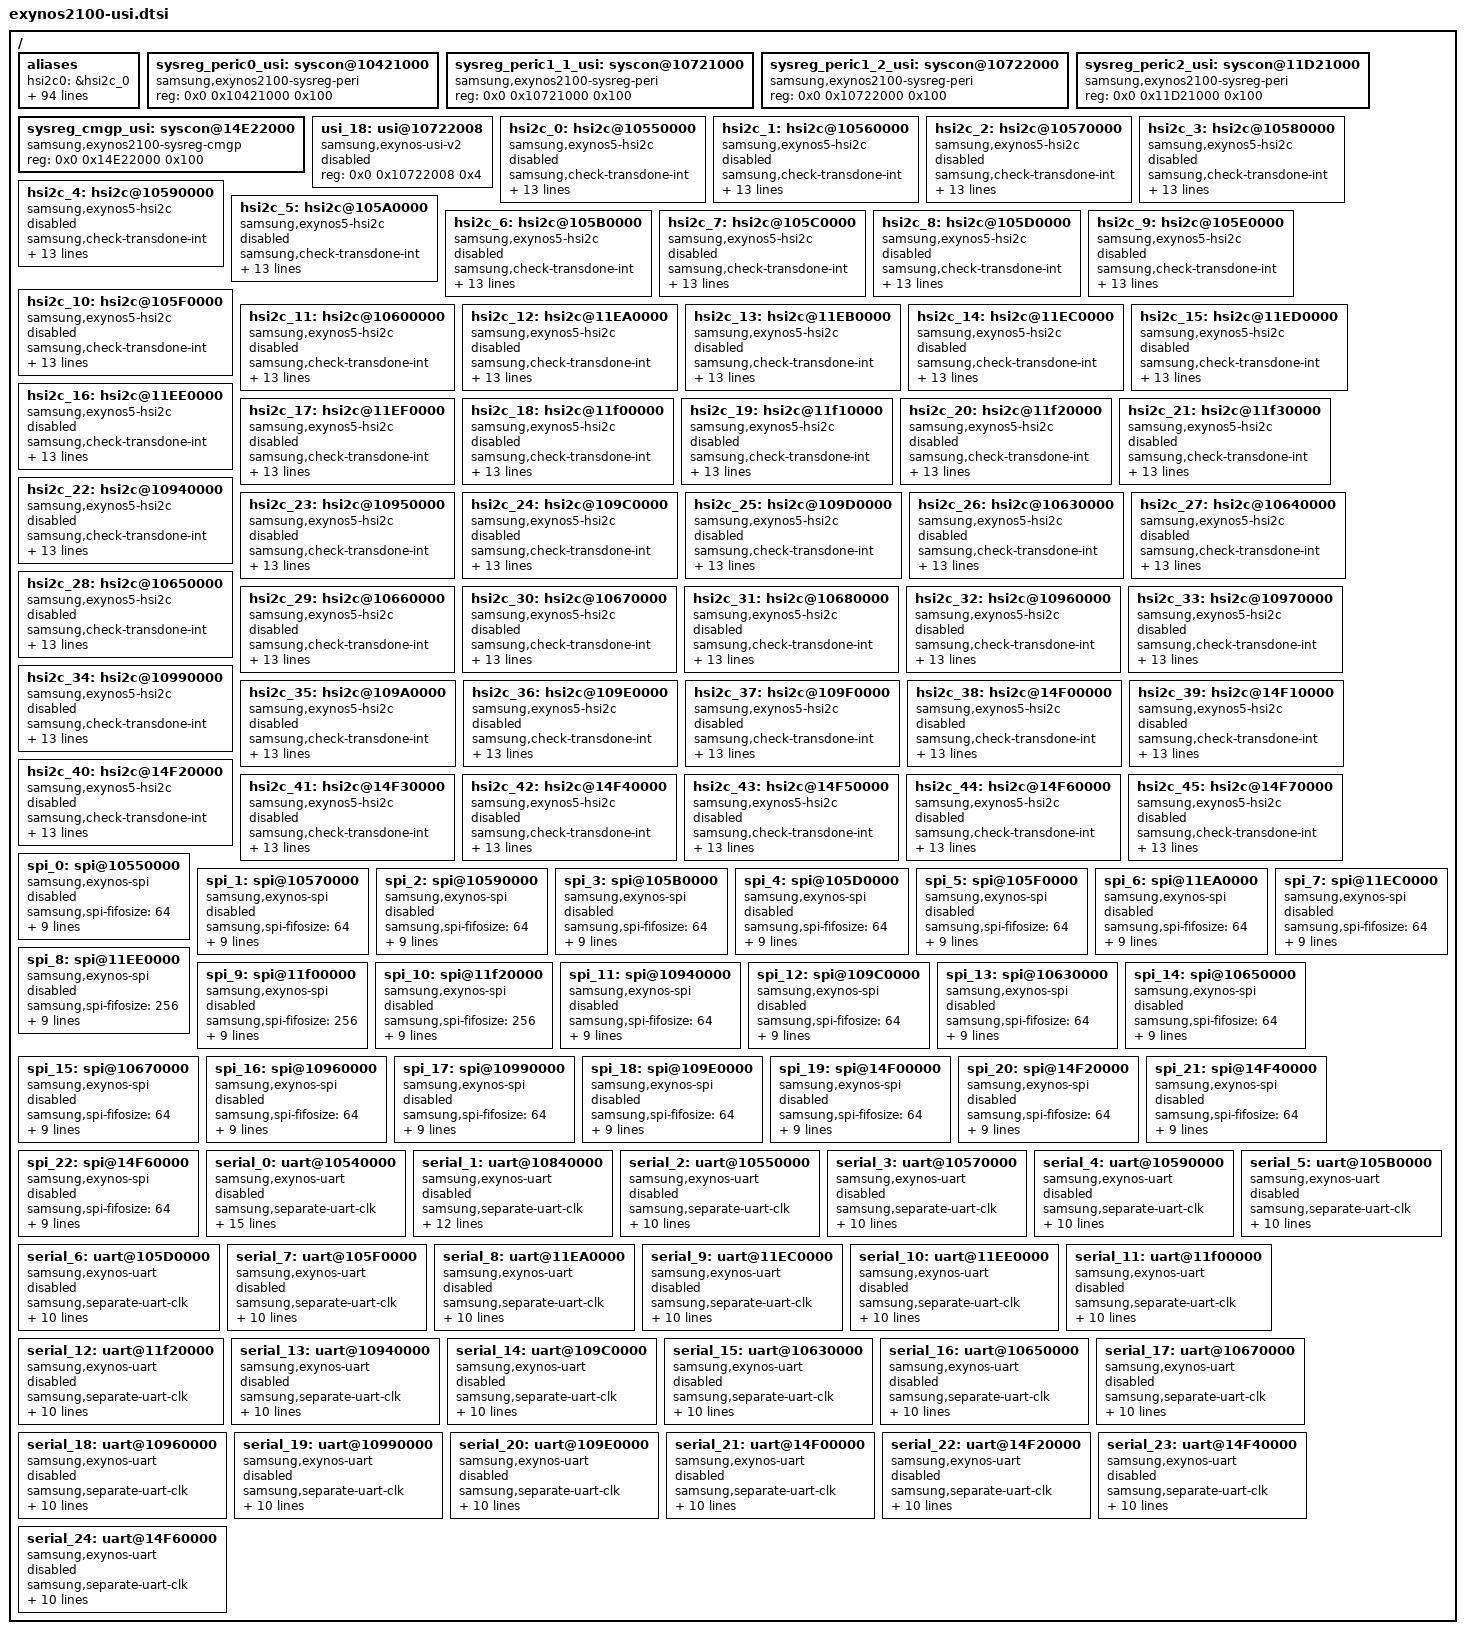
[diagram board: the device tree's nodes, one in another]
/*
 * Samsung's Exynos9830 SoC USI device tree source
 *
 * Copyright (c) 2019 Samsung Electronics Co., Ltd.
 *		http://www.samsung.com
 *
 * Samsung's Exynos9830 SoC USI channels are listed as device
 * tree nodes are listed in this file.
 *
 * This program is free software; you can redistribute it and/or modify
 * it under the terms of the GNU General Public License version 2 as
 * published by the Free Software Foundation.
*/

/ {
	aliases {
		hsi2c0 = &hsi2c_0;
		hsi2c1 = &hsi2c_1;
		hsi2c2 = &hsi2c_2;
		hsi2c3 = &hsi2c_3;
		hsi2c4 = &hsi2c_4;
		hsi2c5 = &hsi2c_5;
		hsi2c6 = &hsi2c_6;
		hsi2c7 = &hsi2c_7;
		hsi2c8 = &hsi2c_8;
		hsi2c9 = &hsi2c_9;
		hsi2c10 = &hsi2c_10;
		hsi2c11 = &hsi2c_11;
		hsi2c12 = &hsi2c_12;
		hsi2c13 = &hsi2c_13;
		hsi2c14 = &hsi2c_14;
		hsi2c15 = &hsi2c_15;
		hsi2c16 = &hsi2c_16;
		hsi2c17 = &hsi2c_17;
		hsi2c18 = &hsi2c_18;
		hsi2c19 = &hsi2c_19;
		hsi2c20 = &hsi2c_20;
		hsi2c21 = &hsi2c_21;
		hsi2c22 = &hsi2c_22;
		hsi2c23 = &hsi2c_23;
		hsi2c24 = &hsi2c_24;
		hsi2c25 = &hsi2c_25;
		hsi2c26 = &hsi2c_26;
		hsi2c27 = &hsi2c_27;
		hsi2c28 = &hsi2c_28;
		hsi2c29 = &hsi2c_29;
		hsi2c30 = &hsi2c_30;
		hsi2c31 = &hsi2c_31;
		hsi2c32 = &hsi2c_32;
		hsi2c33 = &hsi2c_33;
		hsi2c34 = &hsi2c_34;
		hsi2c35 = &hsi2c_35;
		hsi2c36 = &hsi2c_36;
		hsi2c37 = &hsi2c_37;
		hsi2c38 = &hsi2c_38;
		hsi2c39 = &hsi2c_39;
		hsi2c40 = &hsi2c_40;
		hsi2c41 = &hsi2c_41;
		hsi2c42 = &hsi2c_42;
		hsi2c43 = &hsi2c_43;
		hsi2c44 = &hsi2c_44;
		hsi2c45 = &hsi2c_45;
		spi0 = &spi_0;
		spi1 = &spi_1;
		spi2 = &spi_2;
		spi3 = &spi_3;
		spi4 = &spi_4;
		spi5 = &spi_5;
		spi6 = &spi_6;
		spi7 = &spi_7;
		spi8 = &spi_8;
		spi9 = &spi_9;
		spi10 = &spi_10;
		spi11 = &spi_11;
		spi12 = &spi_12;
		spi13 = &spi_13;
		spi14 = &spi_14;
		spi15 = &spi_15;
		spi16 = &spi_16;
		spi17 = &spi_17;
		spi18 = &spi_18;
		spi19 = &spi_19;
		spi20 = &spi_20;
		spi21 = &spi_21;
		spi22 = &spi_22;
		uart0 = &serial_0;
		uart1 = &serial_1;
		uart2 = &serial_2;
		uart3 = &serial_3;
		uart4 = &serial_4;
		uart5 = &serial_5;
		uart6 = &serial_6;
		uart7 = &serial_7;
		uart8 = &serial_8;
		uart9 = &serial_9;
		uart10 = &serial_10;
		uart11 = &serial_11;
		uart12 = &serial_12;
		uart13 = &serial_13;
		uart14 = &serial_14;
		uart15 = &serial_15;
		uart16 = &serial_16;
		uart17 = &serial_17;
		uart18 = &serial_18;
		uart19 = &serial_19;
		uart20 = &serial_20;
		uart21 = &serial_21;
		uart22 = &serial_22;
		uart23 = &serial_23;
		uart24 = &serial_24;
		usi18 = &usi_18;
	};

	/* USI_SW_CONF for PERIC0 USI*/
	sysreg_peric0_usi: syscon@10421000 {
		compatible = "samsung,exynos2100-sysreg-peri", "syscon";
		reg = <0x0 0x10421000 0x100>;
	};

	/* USI_SW_CONF for PERIC1-1 USI*/
	sysreg_peric1_1_usi: syscon@10721000 {
		compatible = "samsung,exynos2100-sysreg-peri", "syscon";
		reg = <0x0 0x10721000 0x100>;
	};

	/* USI_SW_CONF for PERIC1-2 USI*/
	sysreg_peric1_2_usi: syscon@10722000 {
		compatible = "samsung,exynos2100-sysreg-peri", "syscon";
		reg = <0x0 0x10722000 0x100>;
	};

	/* USI_SW_CONF for PERIC2 USI*/
	sysreg_peric2_usi: syscon@11D21000 {
		compatible = "samsung,exynos2100-sysreg-peri", "syscon";
		reg = <0x0 0x11D21000 0x100>;
	};

	/* USI_SW_CONF for CMGP USI*/
	sysreg_cmgp_usi: syscon@14E22000 {
		compatible = "samsung,exynos2100-sysreg-cmgp", "syscon";
		reg = <0x0 0x14E22000 0x100>;
	};

	/* USI_18 */
	usi_18: usi@10722008 {
		compatible = "samsung,exynos-usi-v2";
		reg = <0x0 0x10722008 0x4>;
		/*	usi_v2_mode = "i2c" or "spi" or "uart"	*/
		status = "disabled";
	};

	/* USI00_USI */
	hsi2c_0: hsi2c@10550000 {
		compatible = "samsung,exynos5-hsi2c";
		samsung,check-transdone-int;
		default-clk = <200000000>;
		samsung,scl-clk-stretching;
		samsung,reset-before-trans;
		#address-cells = <1>;
		#size-cells = <0>;
		interrupts = <GIC_SPI INTREQ__USI00_USI IRQ_TYPE_LEVEL_HIGH>;
		samsung,usi-phandle = <&sysreg_peric0_usi>;
		samsung,usi-offset = <0x04>;
		reg = <0x0 0x10550000 0x1000>;
		pinctrl-names = "default";
		pinctrl-0 = <&hsi2c0_bus>;
		clocks = <&clock DOUT_DIV_CLK_PERIC0_USI00_USI>, <&clock GATE_PERIC0_TOP0_QCH_USI00_USI>;
		clock-names = "ipclk_hsi2c", "gate_hsi2c_clk";
		gpio_scl= <&gpp0 0 0x1>;
		gpio_sda= <&gpp0 1 0x1>;
		status = "disabled";
	};

	/* USI00_I2C */
	hsi2c_1: hsi2c@10560000 {
		compatible = "samsung,exynos5-hsi2c";
		samsung,check-transdone-int;
		default-clk = <200000000>;
		samsung,scl-clk-stretching;
		samsung,reset-before-trans;
		#address-cells = <1>;
		#size-cells = <0>;
		interrupts = <GIC_SPI INTREQ__USI00_I2C IRQ_TYPE_LEVEL_HIGH>;
		samsung,usi-phandle = <&sysreg_peric0_usi>;
		samsung,usi-offset = <0x08>;
		reg = <0x0 0x10560000 0x1000>;
		pinctrl-names = "default";
		pinctrl-0 = <&hsi2c1_bus>;
		clocks = <&clock DOUT_DIV_CLK_PERIC0_USI_I2C>, <&clock GATE_PERIC0_TOP0_QCH_USI00_I2C>;
		clock-names = "ipclk_hsi2c", "gate_hsi2c_clk";
		gpio_scl= <&gpp0 2 0x1>;
		gpio_sda= <&gpp0 3 0x1>;
		status = "disabled";
	};

	/* USI01_USI */
	hsi2c_2: hsi2c@10570000 {
		compatible = "samsung,exynos5-hsi2c";
		samsung,check-transdone-int;
		default-clk = <200000000>;
		samsung,scl-clk-stretching;
		samsung,reset-before-trans;
		#address-cells = <1>;
		#size-cells = <0>;
		interrupts = <GIC_SPI INTREQ__USI01_USI IRQ_TYPE_LEVEL_HIGH>;
		samsung,usi-phandle = <&sysreg_peric0_usi>;
		samsung,usi-offset = <0x0C>;
		reg = <0x0 0x10570000 0x1000>;
		pinctrl-names = "default";
		pinctrl-0 = <&hsi2c2_bus>;
		clocks = <&clock DOUT_DIV_CLK_PERIC0_USI01_USI>, <&clock GATE_PERIC0_TOP0_QCH_USI01_USI>;
		clock-names = "ipclk_hsi2c", "gate_hsi2c_clk";
		gpio_scl= <&gpp1 0 0x1>;
		gpio_sda= <&gpp1 1 0x1>;
		status = "disabled";
	};

	/* USI01_I2C */
	hsi2c_3: hsi2c@10580000 {
		compatible = "samsung,exynos5-hsi2c";
		samsung,check-transdone-int;
		default-clk = <200000000>;
		samsung,scl-clk-stretching;
		samsung,reset-before-trans;
		#address-cells = <1>;
		#size-cells = <0>;
		interrupts = <GIC_SPI INTREQ__USI01_I2C IRQ_TYPE_LEVEL_HIGH>;
		samsung,usi-phandle = <&sysreg_peric0_usi>;
		samsung,usi-offset = <0x10>;
		reg = <0x0 0x10580000 0x1000>;
		pinctrl-names = "default";
		pinctrl-0 = <&hsi2c3_bus>;
		clocks = <&clock DOUT_DIV_CLK_PERIC0_USI_I2C>, <&clock GATE_PERIC0_TOP0_QCH_USI01_I2C>;
		clock-names = "ipclk_hsi2c", "gate_hsi2c_clk";
		gpio_scl= <&gpp1 2 0x1>;
		gpio_sda= <&gpp1 3 0x1>;
		status = "disabled";
	};

	/* USI02_USI */
	hsi2c_4: hsi2c@10590000 {
		compatible = "samsung,exynos5-hsi2c";
		samsung,check-transdone-int;
		default-clk = <200000000>;
		samsung,scl-clk-stretching;
		samsung,reset-before-trans;
		#address-cells = <1>;
		#size-cells = <0>;
		interrupts = <GIC_SPI INTREQ__USI02_USI IRQ_TYPE_LEVEL_HIGH>;
		samsung,usi-phandle = <&sysreg_peric0_usi>;
		samsung,usi-offset = <0x14>;
		reg = <0x0 0x10590000 0x1000>;
		pinctrl-names = "default";
		pinctrl-0 = <&hsi2c4_bus>;
		clocks = <&clock DOUT_DIV_CLK_PERIC0_USI02_USI>, <&clock GATE_PERIC0_TOP0_QCH_USI02_USI>;
		clock-names = "ipclk_hsi2c", "gate_hsi2c_clk";
		gpio_scl= <&gpp2 0 0x1>;
		gpio_sda= <&gpp2 1 0x1>;
		status = "disabled";
	};

	/* USI02_I2C */
	hsi2c_5: hsi2c@105A0000 {
		compatible = "samsung,exynos5-hsi2c";
		samsung,check-transdone-int;
		default-clk = <200000000>;
		samsung,scl-clk-stretching;
		samsung,reset-before-trans;
		#address-cells = <1>;
		#size-cells = <0>;
		interrupts = <GIC_SPI INTREQ__USI02_I2C IRQ_TYPE_LEVEL_HIGH>;
		samsung,usi-phandle = <&sysreg_peric0_usi>;
		samsung,usi-offset = <0x18>;
		reg = <0x0 0x105a0000 0x1000>;
		pinctrl-names = "default";
		pinctrl-0 = <&hsi2c5_bus>;
		clocks = <&clock DOUT_DIV_CLK_PERIC0_USI_I2C>, <&clock GATE_PERIC0_TOP0_QCH_USI02_I2C>;
		clock-names = "ipclk_hsi2c", "gate_hsi2c_clk";
		gpio_scl= <&gpp2 2 0x1>;
		gpio_sda= <&gpp2 3 0x1>;
		status = "disabled";
	};

	/* USI03_USI */
	hsi2c_6: hsi2c@105B0000 {
		compatible = "samsung,exynos5-hsi2c";
		samsung,check-transdone-int;
		default-clk = <200000000>;
		samsung,scl-clk-stretching;
		samsung,reset-before-trans;
		#address-cells = <1>;
		#size-cells = <0>;
		interrupts = <GIC_SPI INTREQ__USI03_USI IRQ_TYPE_LEVEL_HIGH>;
		samsung,usi-phandle = <&sysreg_peric0_usi>;
		samsung,usi-offset = <0x1C>;
		reg = <0x0 0x105b0000 0x1000>;
		pinctrl-names = "default";
		pinctrl-0 = <&hsi2c6_bus>;
		clocks = <&clock DOUT_DIV_CLK_PERIC0_USI03_USI>, <&clock GATE_PERIC0_TOP0_QCH_USI03_USI>;
		clock-names = "ipclk_hsi2c", "gate_hsi2c_clk";
		gpio_scl= <&gpp3 0 0x1>;
		gpio_sda= <&gpp3 1 0x1>;
		status = "disabled";
	};

	/* USI03_I2C */
	hsi2c_7: hsi2c@105C0000 {
		compatible = "samsung,exynos5-hsi2c";
		samsung,check-transdone-int;
		default-clk = <200000000>;
		samsung,scl-clk-stretching;
		samsung,reset-before-trans;
		#address-cells = <1>;
		#size-cells = <0>;
		interrupts = <GIC_SPI INTREQ__USI03_I2C IRQ_TYPE_LEVEL_HIGH>;
		samsung,usi-phandle = <&sysreg_peric0_usi>;
		samsung,usi-offset = <0x20>;
		reg = <0x0 0x105c0000 0x1000>;
		pinctrl-names = "default";
		pinctrl-0 = <&hsi2c7_bus>;
		clocks = <&clock DOUT_DIV_CLK_PERIC0_USI_I2C>, <&clock GATE_PERIC0_TOP0_QCH_USI03_I2C>;
		clock-names = "ipclk_hsi2c", "gate_hsi2c_clk";
		gpio_scl= <&gpp3 2 0x1>;
		gpio_sda= <&gpp3 3 0x1>;
		status = "disabled";
	};

	/* USI04_USI */
	hsi2c_8: hsi2c@105D0000 {
		compatible = "samsung,exynos5-hsi2c";
		samsung,check-transdone-int;
		default-clk = <200000000>;
		samsung,scl-clk-stretching;
		samsung,reset-before-trans;
		#address-cells = <1>;
		#size-cells = <0>;
		interrupts = <GIC_SPI INTREQ__USI04_USI IRQ_TYPE_LEVEL_HIGH>;
		samsung,usi-phandle = <&sysreg_peric0_usi>;
		samsung,usi-offset = <0x24>;
		reg = <0x0 0x105d0000 0x1000>;
		pinctrl-names = "default";
		pinctrl-0 = <&hsi2c8_bus>;
		clocks = <&clock DOUT_DIV_CLK_PERIC0_USI04_USI>, <&clock GATE_PERIC0_TOP0_QCH_USI04_USI>;
		clock-names = "ipclk_hsi2c", "gate_hsi2c_clk";
		gpio_scl= <&gpp4 0 0x1>;
		gpio_sda= <&gpp4 1 0x1>;
		status = "disabled";
	};

	/* USI04_I2C */
	hsi2c_9: hsi2c@105E0000 {
		compatible = "samsung,exynos5-hsi2c";
		samsung,check-transdone-int;
		default-clk = <200000000>;
		samsung,scl-clk-stretching;
		samsung,reset-before-trans;
		#address-cells = <1>;
		#size-cells = <0>;
		interrupts = <GIC_SPI INTREQ__USI04_I2C IRQ_TYPE_LEVEL_HIGH>;
		samsung,usi-phandle = <&sysreg_peric0_usi>;
		samsung,usi-offset = <0x28>;
		reg = <0x0 0x105e0000 0x1000>;
		pinctrl-names = "default";
		pinctrl-0 = <&hsi2c9_bus>;
		clocks = <&clock DOUT_DIV_CLK_PERIC0_USI_I2C>, <&clock GATE_PERIC0_TOP0_QCH_USI04_I2C>;
		clock-names = "ipclk_hsi2c", "gate_hsi2c_clk";
		gpio_scl= <&gpp4 2 0x1>;
		gpio_sda= <&gpp4 3 0x1>;
		status = "disabled";
	};

	/* USI05_USI */
	hsi2c_10: hsi2c@105F0000 {
		compatible = "samsung,exynos5-hsi2c";
		samsung,check-transdone-int;
		default-clk = <200000000>;
		samsung,scl-clk-stretching;
		samsung,reset-before-trans;
		#address-cells = <1>;
		#size-cells = <0>;
		interrupts = <GIC_SPI INTREQ__USI05_USI IRQ_TYPE_LEVEL_HIGH>;
		samsung,usi-phandle = <&sysreg_peric0_usi>;
		samsung,usi-offset = <0x2C>;
		reg = <0x0 0x105f0000 0x1000>;
		pinctrl-names = "default";
		pinctrl-0 = <&hsi2c10_bus>;
		clocks = <&clock DOUT_DIV_CLK_PERIC0_USI05_USI>, <&clock GATE_PERIC0_TOP0_QCH_USI05_USI>;
		clock-names = "ipclk_hsi2c", "gate_hsi2c_clk";
		gpio_scl= <&gpp5 0 0x1>;
		gpio_sda= <&gpp5 1 0x1>;
		status = "disabled";
	};

	/* USI05_I2C */
	hsi2c_11: hsi2c@10600000 {
		compatible = "samsung,exynos5-hsi2c";
		samsung,check-transdone-int;
		default-clk = <200000000>;
		samsung,scl-clk-stretching;
		samsung,reset-before-trans;
		#address-cells = <1>;
		#size-cells = <0>;
		interrupts = <GIC_SPI INTREQ__USI05_I2C IRQ_TYPE_LEVEL_HIGH>;
		samsung,usi-phandle = <&sysreg_peric0_usi>;
		samsung,usi-offset = <0x30>;
		reg = <0x0 0x10600000 0x1000>;
		pinctrl-names = "default";
		pinctrl-0 = <&hsi2c11_bus>;
		clocks = <&clock DOUT_DIV_CLK_PERIC0_USI_I2C>, <&clock GATE_PERIC0_TOP1_QCH_USI05_I2C>;
		clock-names = "ipclk_hsi2c", "gate_hsi2c_clk";
		gpio_scl= <&gpp5 2 0x1>;
		gpio_sda= <&gpp5 3 0x1>;
		status = "disabled";
	};

	/* USI06_USI */
	hsi2c_12: hsi2c@11EA0000 {
		compatible = "samsung,exynos5-hsi2c";
		samsung,check-transdone-int;
		default-clk = <200000000>;
		samsung,scl-clk-stretching;
		samsung,reset-before-trans;
		#address-cells = <1>;
		#size-cells = <0>;
		interrupts = <GIC_SPI INTREQ__USI06_USI IRQ_TYPE_LEVEL_HIGH>;
		samsung,usi-phandle = <&sysreg_peric2_usi>;
		samsung,usi-offset = <0x00>;
		reg = <0x0 0x11ea0000 0x1000>;
		pinctrl-names = "default";
		pinctrl-0 = <&hsi2c12_bus>;
		clocks = <&clock DOUT_DIV_CLK_PERIC2_USI06_USI>, <&clock GATE_PERIC2_TOP0_QCH_USI06_USI>;
		clock-names = "ipclk_hsi2c", "gate_hsi2c_clk";
		gpio_scl= <&gpp6 0 0x1>;
		gpio_sda= <&gpp6 1 0x1>;
		status = "disabled";
	};

	/* USI06_I2C */
	hsi2c_13: hsi2c@11EB0000 {
		compatible = "samsung,exynos5-hsi2c";
		samsung,check-transdone-int;
		default-clk = <200000000>;
		samsung,scl-clk-stretching;
		samsung,reset-before-trans;
		#address-cells = <1>;
		#size-cells = <0>;
		interrupts = <GIC_SPI INTREQ__USI06_I2C IRQ_TYPE_LEVEL_HIGH>;
		samsung,usi-phandle = <&sysreg_peric2_usi>;
		samsung,usi-offset = <0x04>;
		reg = <0x0 0x11eb0000 0x1000>;
		pinctrl-names = "default";
		pinctrl-0 = <&hsi2c13_bus>;
		clocks = <&clock DOUT_DIV_CLK_PERIC2_USI_I2C>, <&clock GATE_PERIC2_TOP0_QCH_USI06_I2C>;
		clock-names = "ipclk_hsi2c", "gate_hsi2c_clk";
		gpio_scl= <&gpp6 2 0x1>;
		gpio_sda= <&gpp6 3 0x1>;
		status = "disabled";
	};

	/* USI07_USI */
	hsi2c_14: hsi2c@11EC0000 {
		compatible = "samsung,exynos5-hsi2c";
		samsung,check-transdone-int;
		default-clk = <200000000>;
		samsung,scl-clk-stretching;
		samsung,reset-before-trans;
		#address-cells = <1>;
		#size-cells = <0>;
		interrupts = <GIC_SPI INTREQ__USI07_USI IRQ_TYPE_LEVEL_HIGH>;
		samsung,usi-phandle = <&sysreg_peric2_usi>;
		samsung,usi-offset = <0x08>;
		reg = <0x0 0x11ec0000 0x1000>;
		pinctrl-names = "default";
		pinctrl-0 = <&hsi2c14_bus>;
		clocks = <&clock DOUT_DIV_CLK_PERIC2_USI07_USI>, <&clock GATE_PERIC2_TOP0_QCH_USI07_USI>;
		clock-names = "ipclk_hsi2c", "gate_hsi2c_clk";
		gpio_scl= <&gpp7 0 0x1>;
		gpio_sda= <&gpp7 1 0x1>;
		status = "disabled";
	};

	/* USI07_I2C */
	hsi2c_15: hsi2c@11ED0000 {
		compatible = "samsung,exynos5-hsi2c";
		samsung,check-transdone-int;
		default-clk = <200000000>;
		samsung,scl-clk-stretching;
		samsung,reset-before-trans;
		#address-cells = <1>;
		#size-cells = <0>;
		interrupts = <GIC_SPI INTREQ__USI07_I2C IRQ_TYPE_LEVEL_HIGH>;
		samsung,usi-phandle = <&sysreg_peric2_usi>;
		samsung,usi-offset = <0x0c>;
		reg = <0x0 0x11ed0000 0x1000>;
		pinctrl-names = "default";
		pinctrl-0 = <&hsi2c15_bus>;
		clocks = <&clock DOUT_DIV_CLK_PERIC2_USI_I2C>, <&clock GATE_PERIC2_TOP0_QCH_USI07_I2C>;
		clock-names = "ipclk_hsi2c", "gate_hsi2c_clk";
		gpio_scl= <&gpp7 2 0x1>;
		gpio_sda= <&gpp7 3 0x1>;
		status = "disabled";
	};

	/* USI08_USI */
	hsi2c_16: hsi2c@11EE0000 {
		compatible = "samsung,exynos5-hsi2c";
		samsung,check-transdone-int;
		default-clk = <200000000>;
		samsung,scl-clk-stretching;
		samsung,reset-before-trans;
		#address-cells = <1>;
		#size-cells = <0>;
		interrupts = <GIC_SPI INTREQ__USI08_USI IRQ_TYPE_LEVEL_HIGH>;
		samsung,usi-phandle = <&sysreg_peric2_usi>;
		samsung,usi-offset = <0x10>;
		reg = <0x0 0x11ee0000 0x1000>;
		pinctrl-names = "default";
		pinctrl-0 = <&hsi2c16_bus>;
		clocks = <&clock DOUT_DIV_CLK_PERIC2_USI08_USI>, <&clock GATE_PERIC2_TOP0_QCH_USI08_USI>;
		clock-names = "ipclk_hsi2c", "gate_hsi2c_clk";
		gpio_scl= <&gpp8 0 0x1>;
		gpio_sda= <&gpp8 1 0x1>;
		status = "disabled";
	};

	/* USI08_I2C */
	hsi2c_17: hsi2c@11EF0000 {
		compatible = "samsung,exynos5-hsi2c";
		samsung,check-transdone-int;
		default-clk = <200000000>;
		samsung,scl-clk-stretching;
		samsung,reset-before-trans;
		#address-cells = <1>;
		#size-cells = <0>;
		interrupts = <GIC_SPI INTREQ__USI08_I2C IRQ_TYPE_LEVEL_HIGH>;
		samsung,usi-phandle = <&sysreg_peric2_usi>;
		samsung,usi-offset = <0x14>;
		reg = <0x0 0x11ef0000 0x1000>;
		pinctrl-names = "default";
		pinctrl-0 = <&hsi2c17_bus>;
		clocks = <&clock DOUT_DIV_CLK_PERIC2_USI_I2C>, <&clock GATE_PERIC2_TOP0_QCH_USI08_I2C>;
		clock-names = "ipclk_hsi2c", "gate_hsi2c_clk";
		gpio_scl= <&gpp8 2 0x1>;
		gpio_sda= <&gpp8 3 0x1>;
		status = "disabled";
	};

	/* USI09_USI */
	hsi2c_18: hsi2c@11f00000 {
		compatible = "samsung,exynos5-hsi2c";
		samsung,check-transdone-int;
		default-clk = <200000000>;
		samsung,scl-clk-stretching;
		samsung,reset-before-trans;
		#address-cells = <1>;
		#size-cells = <0>;
		interrupts = <GIC_SPI INTREQ__USI09_USI IRQ_TYPE_LEVEL_HIGH>;
		samsung,usi-phandle = <&sysreg_peric2_usi>;
		samsung,usi-offset = <0x18>;
		reg = <0x0 0x11f00000 0x1000>;
		pinctrl-names = "default";
		pinctrl-0 = <&hsi2c18_bus>;
		clocks = <&clock DOUT_DIV_CLK_PERIC2_USI09_USI>, <&clock GATE_PERIC2_TOP1_QCH_USI09_USI>;
		clock-names = "ipclk_hsi2c", "gate_hsi2c_clk";
		gpio_scl= <&gpp9 0 0x1>;
		gpio_sda= <&gpp9 1 0x1>;
		status = "disabled";
	};

	/* USI09_I2C */
	hsi2c_19: hsi2c@11f10000 {
		compatible = "samsung,exynos5-hsi2c";
		samsung,check-transdone-int;
		default-clk = <200000000>;
		samsung,scl-clk-stretching;
		samsung,reset-before-trans;
		#address-cells = <1>;
		#size-cells = <0>;
		interrupts = <GIC_SPI INTREQ__USI09_I2C IRQ_TYPE_LEVEL_HIGH>;
		samsung,usi-phandle = <&sysreg_peric2_usi>;
		samsung,usi-offset = <0x1c>;
		reg = <0x0 0x11f10000 0x1000>;
		pinctrl-names = "default";
		pinctrl-0 = <&hsi2c19_bus>;
		clocks = <&clock DOUT_DIV_CLK_PERIC2_USI_I2C>, <&clock GATE_PERIC2_TOP1_QCH_USI09_I2C>;
		clock-names = "ipclk_hsi2c", "gate_hsi2c_clk";
		gpio_scl= <&gpp9 2 0x1>;
		gpio_sda= <&gpp9 3 0x1>;
		status = "disabled";
	};

	/* USI10_USI */
	hsi2c_20: hsi2c@11f20000 {
		compatible = "samsung,exynos5-hsi2c";
		samsung,check-transdone-int;
		default-clk = <200000000>;
		samsung,scl-clk-stretching;
		samsung,reset-before-trans;
		#address-cells = <1>;
		#size-cells = <0>;
		interrupts = <GIC_SPI INTREQ__USI10_USI IRQ_TYPE_LEVEL_HIGH>;
		samsung,usi-phandle = <&sysreg_peric2_usi>;
		samsung,usi-offset = <0x20>;
		reg = <0x0 0x11f20000 0x1000>;
		pinctrl-names = "default";
		pinctrl-0 = <&hsi2c20_bus>;
		clocks = <&clock DOUT_DIV_CLK_PERIC2_USI10_USI>, <&clock GATE_PERIC2_TOP1_QCH_USI10_USI>;
		clock-names = "ipclk_hsi2c", "gate_hsi2c_clk";
		gpio_scl= <&gpp10 0 0x1>;
		gpio_sda= <&gpp10 1 0x1>;
		status = "disabled";
	};

	/* USI10_I2C */
	hsi2c_21: hsi2c@11f30000 {
		compatible = "samsung,exynos5-hsi2c";
		samsung,check-transdone-int;
		default-clk = <200000000>;
		samsung,scl-clk-stretching;
		samsung,reset-before-trans;
		#address-cells = <1>;
		#size-cells = <0>;
		interrupts = <GIC_SPI INTREQ__USI10_I2C IRQ_TYPE_LEVEL_HIGH>;
		samsung,usi-phandle = <&sysreg_peric2_usi>;
		samsung,usi-offset = <0x24>;
		reg = <0x0 0x11f30000 0x1000>;
		pinctrl-names = "default";
		pinctrl-0 = <&hsi2c21_bus>;
		clocks = <&clock DOUT_DIV_CLK_PERIC2_USI_I2C>, <&clock GATE_PERIC2_TOP1_QCH_USI10_I2C>;
		clock-names = "ipclk_hsi2c", "gate_hsi2c_clk";
		gpio_scl= <&gpp10 2 0x1>;
		gpio_sda= <&gpp10 3 0x1>;
		status = "disabled";
	};

	/* USI11_USI */
	hsi2c_22: hsi2c@10940000 {
		compatible = "samsung,exynos5-hsi2c";
		samsung,check-transdone-int;
		default-clk = <200000000>;
		samsung,scl-clk-stretching;
		samsung,reset-before-trans;
		#address-cells = <1>;
		#size-cells = <0>;
		interrupts = <GIC_SPI INTREQ__USI11_USI IRQ_TYPE_LEVEL_HIGH>;
		samsung,usi-phandle = <&sysreg_peric1_1_usi>;
		samsung,usi-offset = <0x28>;
		reg = <0x0 0x10940000 0x1000>;
		pinctrl-names = "default";
		pinctrl-0 = <&hsi2c22_bus>;
		clocks = <&clock DOUT_DIV_CLK_PERIC1_USI11_USI>, <&clock GATE_PERIC1_TOP1_QCH_USI11_USI>;
		clock-names = "ipclk_hsi2c", "gate_hsi2c_clk";
		gpio_scl= <&gpp11 0 0x1>;
		gpio_sda= <&gpp11 1 0x1>;
		status = "disabled";
	};

	/* USI11_I2C */
	hsi2c_23: hsi2c@10950000 {
		compatible = "samsung,exynos5-hsi2c";
		samsung,check-transdone-int;
		default-clk = <200000000>;
		samsung,scl-clk-stretching;
		samsung,reset-before-trans;
		#address-cells = <1>;
		#size-cells = <0>;
		interrupts = <GIC_SPI INTREQ__USI11_I2C IRQ_TYPE_LEVEL_HIGH>;
		samsung,usi-phandle = <&sysreg_peric1_1_usi>;
		samsung,usi-offset = <0x2c>;
		reg = <0x0 0x10950000 0x1000>;
		pinctrl-names = "default";
		pinctrl-0 = <&hsi2c23_bus>;
		clocks = <&clock DOUT_DIV_CLK_PERIC1_USI_I2C>, <&clock GATE_PERIC1_TOP1_QCH_USI11_I2C>;
		clock-names = "ipclk_hsi2c", "gate_hsi2c_clk";
		gpio_scl= <&gpp11 2 0x1>;
		gpio_sda= <&gpp11 3 0x1>;
		status = "disabled";
	};

	/* USI12_USI */
	hsi2c_24: hsi2c@109C0000 {
		compatible = "samsung,exynos5-hsi2c";
		samsung,check-transdone-int;
		default-clk = <200000000>;
		samsung,scl-clk-stretching;
		samsung,reset-before-trans;
		#address-cells = <1>;
		#size-cells = <0>;
		interrupts = <GIC_SPI INTREQ__USI12_USI IRQ_TYPE_LEVEL_HIGH>;
		samsung,usi-phandle = <&sysreg_peric1_2_usi>;
		samsung,usi-offset = <0x00>;
		reg = <0x0 0x109c0000 0x1000>;
		pinctrl-names = "default";
		pinctrl-0 = <&hsi2c24_bus>;
		clocks = <&clock DOUT_DIV_CLK_PERIC1_USI12_USI>, <&clock GATE_PERIC1_TOP1_QCH_USI12_USI>;
		clock-names = "ipclk_hsi2c", "gate_hsi2c_clk";
		gpio_scl= <&gpp12 0 0x1>;
		gpio_sda= <&gpp12 1 0x1>;
		status = "disabled";
	};

	/* USI12_I2C */
	hsi2c_25: hsi2c@109D0000 {
		compatible = "samsung,exynos5-hsi2c";
		samsung,check-transdone-int;
		default-clk = <200000000>;
		samsung,scl-clk-stretching;
		samsung,reset-before-trans;
		#address-cells = <1>;
		#size-cells = <0>;
		interrupts = <GIC_SPI INTREQ__USI12_I2C IRQ_TYPE_LEVEL_HIGH>;
		samsung,usi-phandle = <&sysreg_peric1_2_usi>;
		samsung,usi-offset = <0x04>;
		reg = <0x0 0x109d0000 0x1000>;
		pinctrl-names = "default";
		pinctrl-0 = <&hsi2c25_bus>;
		clocks = <&clock DOUT_DIV_CLK_PERIC1_USI_I2C>, <&clock GATE_PERIC1_TOP1_QCH_USI12_I2C>;
		clock-names = "ipclk_hsi2c", "gate_hsi2c_clk";
		gpio_scl= <&gpp12 2 0x1>;
		gpio_sda= <&gpp12 3 0x1>;
		status = "disabled";
	};

	/* USI13_USI */
	hsi2c_26: hsi2c@10630000 {
		compatible = "samsung,exynos5-hsi2c";
		samsung,check-transdone-int;
		default-clk = <200000000>;
		samsung,scl-clk-stretching;
		samsung,reset-before-trans;
		#address-cells = <1>;
		#size-cells = <0>;
		interrupts = <GIC_SPI INTREQ__USI13_USI IRQ_TYPE_LEVEL_HIGH>;
		samsung,usi-phandle = <&sysreg_peric0_usi>;
		samsung,usi-offset = <0x3C>;
		reg = <0x0 0x10630000 0x1000>;
		pinctrl-names = "default";
		pinctrl-0 = <&hsi2c26_bus>;
		clocks = <&clock DOUT_DIV_CLK_PERIC0_USI13_USI>, <&clock GATE_PERIC0_TOP1_QCH_USI13_USI>;
		clock-names = "ipclk_hsi2c", "gate_hsi2c_clk";
		gpio_scl= <&gpp13 0 0x1>;
		gpio_sda= <&gpp13 1 0x1>;
		status = "disabled";
	};

	/* USI13_I2C */
	hsi2c_27: hsi2c@10640000 {
		compatible = "samsung,exynos5-hsi2c";
		samsung,check-transdone-int;
		default-clk = <200000000>;
		samsung,scl-clk-stretching;
		samsung,reset-before-trans;
		#address-cells = <1>;
		#size-cells = <0>;
		interrupts = <GIC_SPI INTREQ__USI13_I2C IRQ_TYPE_LEVEL_HIGH>;
		samsung,usi-phandle = <&sysreg_peric0_usi>;
		samsung,usi-offset = <0x40>;
		reg = <0x0 0x10640000 0x1000>;
		pinctrl-names = "default";
		pinctrl-0 = <&hsi2c27_bus>;
		clocks = <&clock DOUT_DIV_CLK_PERIC0_USI_I2C>, <&clock GATE_PERIC0_TOP1_QCH_USI13_I2C>;
		clock-names = "ipclk_hsi2c", "gate_hsi2c_clk";
		gpio_scl= <&gpp13 2 0x1>;
		gpio_sda= <&gpp13 3 0x1>;
		status = "disabled";
	};

	/* USI14_USI */
	hsi2c_28: hsi2c@10650000 {
		compatible = "samsung,exynos5-hsi2c";
		samsung,check-transdone-int;
		default-clk = <200000000>;
		samsung,scl-clk-stretching;
		samsung,reset-before-trans;
		#address-cells = <1>;
		#size-cells = <0>;
		interrupts = <GIC_SPI INTREQ__USI14_USI IRQ_TYPE_LEVEL_HIGH>;
		samsung,usi-phandle = <&sysreg_peric0_usi>;
		samsung,usi-offset = <0x44>;
		reg = <0x0 0x10650000 0x1000>;
		pinctrl-names = "default";
		pinctrl-0 = <&hsi2c28_bus>;
		clocks = <&clock DOUT_DIV_CLK_PERIC0_USI14_USI>, <&clock GATE_PERIC0_TOP1_QCH_USI14_USI>;
		clock-names = "ipclk_hsi2c", "gate_hsi2c_clk";
		gpio_scl= <&gpp14 0 0x1>;
		gpio_sda= <&gpp14 1 0x1>;
		status = "disabled";
	};

	/* USI14_I2C */
	hsi2c_29: hsi2c@10660000 {
		compatible = "samsung,exynos5-hsi2c";
		samsung,check-transdone-int;
		default-clk = <200000000>;
		samsung,scl-clk-stretching;
		samsung,reset-before-trans;
		#address-cells = <1>;
		#size-cells = <0>;
		interrupts = <GIC_SPI INTREQ__USI14_I2C IRQ_TYPE_LEVEL_HIGH>;
		samsung,usi-phandle = <&sysreg_peric0_usi>;
		samsung,usi-offset = <0x48>;
		reg = <0x0 0x10660000 0x1000>;
		pinctrl-names = "default";
		pinctrl-0 = <&hsi2c29_bus>;
		clocks = <&clock DOUT_DIV_CLK_PERIC0_USI_I2C>, <&clock GATE_PERIC0_TOP1_QCH_USI14_I2C>;
		clock-names = "ipclk_hsi2c", "gate_hsi2c_clk";
		gpio_scl= <&gpp14 2 0x1>;
		gpio_sda= <&gpp14 3 0x1>;
		status = "disabled";
	};

	/* USI15_USI */
	hsi2c_30: hsi2c@10670000 {
		compatible = "samsung,exynos5-hsi2c";
		samsung,check-transdone-int;
		default-clk = <200000000>;
		samsung,scl-clk-stretching;
		samsung,reset-before-trans;
		#address-cells = <1>;
		#size-cells = <0>;
		interrupts = <GIC_SPI INTREQ__USI15_USI IRQ_TYPE_LEVEL_HIGH>;
		samsung,usi-phandle = <&sysreg_peric0_usi>;
		samsung,usi-offset = <0x4C>;
		reg = <0x0 0x10670000 0x1000>;
		pinctrl-names = "default";
		pinctrl-0 = <&hsi2c30_bus>;
		clocks = <&clock DOUT_DIV_CLK_PERIC0_USI15_USI>, <&clock GATE_PERIC0_TOP1_QCH_USI15_USI>;
		clock-names = "ipclk_hsi2c", "gate_hsi2c_clk";
		gpio_scl= <&gpp15 0 0x1>;
		gpio_sda= <&gpp15 1 0x1>;
		status = "disabled";
	};

	/* USI15_I2C */
	hsi2c_31: hsi2c@10680000 {
		compatible = "samsung,exynos5-hsi2c";
		samsung,check-transdone-int;
		default-clk = <200000000>;
		samsung,scl-clk-stretching;
		samsung,reset-before-trans;
		#address-cells = <1>;
		#size-cells = <0>;
		interrupts = <GIC_SPI INTREQ__USI15_I2C IRQ_TYPE_LEVEL_HIGH>;
		samsung,usi-phandle = <&sysreg_peric0_usi>;
		samsung,usi-offset = <0x50>;
		reg = <0x0 0x10680000 0x1000>;
		pinctrl-names = "default";
		pinctrl-0 = <&hsi2c31_bus>;
		clocks = <&clock DOUT_DIV_CLK_PERIC0_USI_I2C>, <&clock GATE_PERIC0_TOP1_QCH_USI15_I2C>;
		clock-names = "ipclk_hsi2c", "gate_hsi2c_clk";
		gpio_scl= <&gpp15 2 0x1>;
		gpio_sda= <&gpp15 3 0x1>;
		status = "disabled";
	};

	/* USI16_USI */
	hsi2c_32: hsi2c@10960000 {
		compatible = "samsung,exynos5-hsi2c";
		samsung,check-transdone-int;
		default-clk = <200000000>;
		samsung,scl-clk-stretching;
		samsung,reset-before-trans;
		#address-cells = <1>;
		#size-cells = <0>;
		interrupts = <GIC_SPI INTREQ__USI16_USI IRQ_TYPE_LEVEL_HIGH>;
		samsung,usi-phandle = <&sysreg_peric1_1_usi>;
		samsung,usi-offset = <0x30>;
		reg = <0x0 0x10960000 0x1000>;
		pinctrl-names = "default";
		pinctrl-0 = <&hsi2c32_bus>;
		clocks = <&clock DOUT_DIV_CLK_PERIC1_USI16_USI>, <&clock GATE_PERIC1_TOP1_QCH_USI16_USI>;
		clock-names = "ipclk_hsi2c", "gate_hsi2c_clk";
		gpio_scl= <&gpp16 0 0x1>;
		gpio_sda= <&gpp16 1 0x1>;
		status = "disabled";
	};

	/* USI16_I2C */
	hsi2c_33: hsi2c@10970000 {
		compatible = "samsung,exynos5-hsi2c";
		samsung,check-transdone-int;
		default-clk = <200000000>;
		samsung,scl-clk-stretching;
		samsung,reset-before-trans;
		#address-cells = <1>;
		#size-cells = <0>;
		interrupts = <GIC_SPI INTREQ__USI16_I2C IRQ_TYPE_LEVEL_HIGH>;
		samsung,usi-phandle = <&sysreg_peric1_1_usi>;
		samsung,usi-offset = <0x34>;
		reg = <0x0 0x10970000 0x1000>;
		pinctrl-names = "default";
		pinctrl-0 = <&hsi2c33_bus>;
		clocks = <&clock DOUT_DIV_CLK_PERIC1_USI_I2C>, <&clock GATE_PERIC1_TOP1_QCH_USI16_I2C>;
		clock-names = "ipclk_hsi2c", "gate_hsi2c_clk";
		gpio_scl= <&gpp16 2 0x1>;
		gpio_sda= <&gpp16 3 0x1>;
		status = "disabled";
	};

	/* USI17_USI */
	hsi2c_34: hsi2c@10990000 {
		compatible = "samsung,exynos5-hsi2c";
		samsung,check-transdone-int;
		default-clk = <200000000>;
		samsung,scl-clk-stretching;
		samsung,reset-before-trans;
		#address-cells = <1>;
		#size-cells = <0>;
		interrupts = <GIC_SPI INTREQ__USI17_USI IRQ_TYPE_LEVEL_HIGH>;
		samsung,usi-phandle = <&sysreg_peric1_1_usi>;
		samsung,usi-offset = <0x38>;
		reg = <0x0 0x10990000 0x1000>;
		pinctrl-names = "default";
		pinctrl-0 = <&hsi2c34_bus>;
		clocks = <&clock DOUT_DIV_CLK_PERIC1_USI17_USI>, <&clock GATE_PERIC1_TOP1_QCH_USI17_USI>;
		clock-names = "ipclk_hsi2c", "gate_hsi2c_clk";
		gpio_scl= <&gpp17 0 0x1>;
		gpio_sda= <&gpp17 1 0x1>;
		status = "disabled";
	};

	/* USI17_I2C */
	hsi2c_35: hsi2c@109A0000 {
		compatible = "samsung,exynos5-hsi2c";
		samsung,check-transdone-int;
		default-clk = <200000000>;
		samsung,scl-clk-stretching;
		samsung,reset-before-trans;
		#address-cells = <1>;
		#size-cells = <0>;
		interrupts = <GIC_SPI INTREQ__USI17_I2C IRQ_TYPE_LEVEL_HIGH>;
		samsung,usi-phandle = <&sysreg_peric1_1_usi>;
		samsung,usi-offset = <0x3c>;
		reg = <0x0 0x109a0000 0x1000>;
		pinctrl-names = "default";
		pinctrl-0 = <&hsi2c35_bus>;
		clocks = <&clock DOUT_DIV_CLK_PERIC1_USI_I2C>, <&clock GATE_PERIC1_TOP1_QCH_USI17_I2C>;
		clock-names = "ipclk_hsi2c", "gate_hsi2c_clk";
		gpio_scl= <&gpp17 2 0x1>;
		gpio_sda= <&gpp17 3 0x1>;
		status = "disabled";
	};

	/* USI18_USI */
	hsi2c_36: hsi2c@109E0000 {
		compatible = "samsung,exynos5-hsi2c";
		samsung,check-transdone-int;
		default-clk = <200000000>;
		samsung,scl-clk-stretching;
		samsung,reset-before-trans;
		#address-cells = <1>;
		#size-cells = <0>;
		interrupts = <GIC_SPI INTREQ__USI18_USI IRQ_TYPE_LEVEL_HIGH>;
		samsung,usi-phandle = <&sysreg_peric1_2_usi>;
		samsung,usi-offset = <0x08>;
		reg = <0x0 0x109e0000 0x1000>;
		pinctrl-names = "default";
		pinctrl-0 = <&hsi2c36_bus>;
		clocks = <&clock DOUT_DIV_CLK_PERIC1_USI18_USI>, <&clock GATE_PERIC1_TOP1_QCH_USI18_USI>;
		clock-names = "ipclk_hsi2c", "gate_hsi2c_clk";
		gpio_scl= <&gpp18 0 0x1>;
		gpio_sda= <&gpp18 1 0x1>;
		status = "disabled";
	};

	/* USI18_I2C */
	hsi2c_37: hsi2c@109F0000 {
		compatible = "samsung,exynos5-hsi2c";
		samsung,check-transdone-int;
		default-clk = <200000000>;
		samsung,scl-clk-stretching;
		samsung,reset-before-trans;
		#address-cells = <1>;
		#size-cells = <0>;
		interrupts = <GIC_SPI INTREQ__USI18_I2C IRQ_TYPE_LEVEL_HIGH>;
		samsung,usi-phandle = <&sysreg_peric1_2_usi>;
		samsung,usi-offset = <0x0c>;
		reg = <0x0 0x109f0000 0x1000>;
		pinctrl-names = "default";
		pinctrl-0 = <&hsi2c37_bus>;
		clocks = <&clock DOUT_DIV_CLK_PERIC1_USI_I2C>, <&clock GATE_PERIC1_TOP1_QCH_USI18_I2C>;
		clock-names = "ipclk_hsi2c", "gate_hsi2c_clk";
		gpio_scl= <&gpp18 2 0x1>;
		gpio_sda= <&gpp18 3 0x1>;
		status = "disabled";
	};

	/* USI_CMGP00 */
	hsi2c_38: hsi2c@14F00000 {
		compatible = "samsung,exynos5-hsi2c";
		samsung,check-transdone-int;
		default-clk = <200000000>;
		samsung,scl-clk-stretching;
		samsung,reset-before-trans;
		#address-cells = <1>;
		#size-cells = <0>;
		interrupts = <GIC_SPI INTREQ__USI_CMGP0 IRQ_TYPE_LEVEL_HIGH>;
		samsung,usi-phandle = <&sysreg_cmgp_usi>;
		samsung,usi-offset = <0x00>;
		reg = <0x0 0x14f00000 0x1000>;
		pinctrl-names = "default";
		pinctrl-0 = <&hsi2c38_bus>;
		clocks = <&clock DOUT_DIV_CLK_CMGP_USI0>, <&clock GATE_USI_CMGP0_QCH>;
		clock-names = "ipclk_hsi2c", "gate_hsi2c_clk";
		gpio_scl= <&gpm0 0 0x1>;
		gpio_sda= <&gpm0 1 0x1>;
		status = "disabled";
	};

	/* I2C_CMGP00 */
	hsi2c_39: hsi2c@14F10000 {
		compatible = "samsung,exynos5-hsi2c";
		samsung,check-transdone-int;
		default-clk = <200000000>;
		samsung,scl-clk-stretching;
		samsung,reset-before-trans;
		#address-cells = <1>;
		#size-cells = <0>;
		interrupts = <GIC_SPI INTREQ__I2C_CMGP0 IRQ_TYPE_LEVEL_HIGH>;
		samsung,usi-phandle = <&sysreg_cmgp_usi>;
		samsung,usi-offset = <0x04>;
		reg = <0x0 0x14f10000 0x1000>;
		pinctrl-names = "default";
		pinctrl-0 = <&hsi2c39_bus>;
		clocks = <&clock DOUT_DIV_CLK_CMGP_I2C0>, <&clock GATE_I2C_CMGP0_QCH>;
		clock-names = "ipclk_hsi2c", "gate_hsi2c_clk";
		gpio_scl= <&gpm1 0 0x1>;
		gpio_sda= <&gpm1 1 0x1>;
		status = "disabled";
	};

	/* USI_CMGP01 */
	hsi2c_40: hsi2c@14F20000 {
		compatible = "samsung,exynos5-hsi2c";
		samsung,check-transdone-int;
		default-clk = <200000000>;
		samsung,scl-clk-stretching;
		samsung,reset-before-trans;
		#address-cells = <1>;
		#size-cells = <0>;
		interrupts = <GIC_SPI INTREQ__USI_CMGP1 IRQ_TYPE_LEVEL_HIGH>;
		samsung,usi-phandle = <&sysreg_cmgp_usi>;
		samsung,usi-offset = <0x10>;
		reg = <0x0 0x14f20000 0x1000>;
		pinctrl-names = "default";
		pinctrl-0 = <&hsi2c40_bus>;
		clocks = <&clock DOUT_DIV_CLK_CMGP_USI1>, <&clock GATE_USI_CMGP1_QCH>;
		clock-names = "ipclk_hsi2c", "gate_hsi2c_clk";
		gpio_scl= <&gpm2 0 0x1>;
		gpio_sda= <&gpm2 1 0x1>;
		status = "disabled";
	};

	/* I2C_CMGP01 */
	hsi2c_41: hsi2c@14F30000 {
		compatible = "samsung,exynos5-hsi2c";
		samsung,check-transdone-int;
		default-clk = <200000000>;
		samsung,scl-clk-stretching;
		samsung,reset-before-trans;
		#address-cells = <1>;
		#size-cells = <0>;
		interrupts = <GIC_SPI INTREQ__I2C_CMGP1 IRQ_TYPE_LEVEL_HIGH>;
		samsung,usi-phandle = <&sysreg_cmgp_usi>;
		samsung,usi-offset = <0x14>;
		reg = <0x0 0x14f30000 0x1000>;
		pinctrl-names = "default";
		pinctrl-0 = <&hsi2c41_bus>;
		clocks = <&clock DOUT_DIV_CLK_CMGP_I2C1>, <&clock GATE_I2C_CMGP1_QCH>;
		clock-names = "ipclk_hsi2c", "gate_hsi2c_clk";
		gpio_scl= <&gpm3 0 0x1>;
		gpio_sda= <&gpm3 1 0x1>;
		status = "disabled";
	};

	/* USI_CMGP02 */
	hsi2c_42: hsi2c@14F40000 {
		compatible = "samsung,exynos5-hsi2c";
		samsung,check-transdone-int;
		default-clk = <200000000>;
		samsung,scl-clk-stretching;
		samsung,reset-before-trans;
		#address-cells = <1>;
		#size-cells = <0>;
		interrupts = <GIC_SPI INTREQ__USI_CMGP2 IRQ_TYPE_LEVEL_HIGH>;
		samsung,usi-phandle = <&sysreg_cmgp_usi>;
		samsung,usi-offset = <0x20>;
		reg = <0x0 0x14f40000 0x1000>;
		pinctrl-names = "default";
		pinctrl-0 = <&hsi2c42_bus>;
		clocks = <&clock DOUT_DIV_CLK_CMGP_USI2>, <&clock GATE_USI_CMGP2_QCH>;
		clock-names = "ipclk_hsi2c", "gate_hsi2c_clk";
		gpio_scl= <&gpm4 0 0x1>;
		gpio_sda= <&gpm4 1 0x1>;
		status = "disabled";
	};

	/* I2C_CMGP02 */
	hsi2c_43: hsi2c@14F50000 {
		compatible = "samsung,exynos5-hsi2c";
		samsung,check-transdone-int;
		default-clk = <200000000>;
		samsung,scl-clk-stretching;
		samsung,reset-before-trans;
		#address-cells = <1>;
		#size-cells = <0>;
		interrupts = <GIC_SPI INTREQ__I2C_CMGP2 IRQ_TYPE_LEVEL_HIGH>;
		samsung,usi-phandle = <&sysreg_cmgp_usi>;
		samsung,usi-offset = <0x24>;
		reg = <0x0 0x14f50000 0x1000>;
		pinctrl-names = "default";
		pinctrl-0 = <&hsi2c43_bus>;
		clocks = <&clock DOUT_DIV_CLK_CMGP_I2C2>, <&clock GATE_I2C_CMGP2_QCH>;
		clock-names = "ipclk_hsi2c", "gate_hsi2c_clk";
		gpio_scl= <&gpm5 0 0x1>;
		gpio_sda= <&gpm5 1 0x1>;
		status = "disabled";
	};

	/* USI_CMGP03 */
	hsi2c_44: hsi2c@14F60000 {
		compatible = "samsung,exynos5-hsi2c";
		samsung,check-transdone-int;
		default-clk = <200000000>;
		samsung,scl-clk-stretching;
		samsung,reset-before-trans;
		#address-cells = <1>;
		#size-cells = <0>;
		interrupts = <GIC_SPI INTREQ__USI_CMGP3 IRQ_TYPE_LEVEL_HIGH>;
		samsung,usi-phandle = <&sysreg_cmgp_usi>;
		samsung,usi-offset = <0x30>;
		reg = <0x0 0x14f60000 0x1000>;
		pinctrl-names = "default";
		pinctrl-0 = <&hsi2c44_bus>;
		clocks = <&clock DOUT_DIV_CLK_CMGP_USI3>, <&clock GATE_USI_CMGP3_QCH>;
		clock-names = "ipclk_hsi2c", "gate_hsi2c_clk";
		gpio_scl= <&gpm6 0 0x1>;
		gpio_sda= <&gpm6 1 0x1>;
		status = "disabled";
	};

	/* I2C_CMGP03 */
	hsi2c_45: hsi2c@14F70000 {
		compatible = "samsung,exynos5-hsi2c";
		samsung,check-transdone-int;
		default-clk = <200000000>;
		samsung,scl-clk-stretching;
		samsung,reset-before-trans;
		#address-cells = <1>;
		#size-cells = <0>;
		interrupts = <GIC_SPI INTREQ__I2C_CMGP3 IRQ_TYPE_LEVEL_HIGH>;
		samsung,usi-phandle = <&sysreg_cmgp_usi>;
		samsung,usi-offset = <0x34>;
		reg = <0x0 0x14f70000 0x1000>;
		pinctrl-names = "default";
		pinctrl-0 = <&hsi2c45_bus>;
		clocks = <&clock DOUT_DIV_CLK_CMGP_I2C3>, <&clock GATE_I2C_CMGP3_QCH>;
		clock-names = "ipclk_hsi2c", "gate_hsi2c_clk";
		gpio_scl= <&gpm7 0 0x1>;
		gpio_sda= <&gpm7 1 0x1>;
		status = "disabled";
	};

	/* USI00_USI */
	spi_0: spi@10550000 {
		compatible = "samsung,exynos-spi";
		samsung,spi-fifosize = <64>;
		swap-mode = <1>;
		#address-cells = <1>;
		#size-cells = <0>;
/*
		dma-mode;
		dmas = <&pdma0 1 &pdma0 0>;
*/
		dma-names = "tx", "rx";
		interrupts = <GIC_SPI INTREQ__USI00_USI IRQ_TYPE_LEVEL_HIGH>;
		samsung,usi-phandle = <&sysreg_peric0_usi>;
		clocks = <&clock GATE_PERIC0_TOP0_QCH_USI00_USI>, <&clock DOUT_DIV_CLK_PERIC0_USI00_USI>;
		clock-names = "gate_spi_clk", "ipclk_spi";
		pinctrl-names = "default";
		pinctrl-0 = <&spi0_bus>;
		samsung,usi-offset = <0x04>;
		reg = <0x0 0x10550000 0x1000>;
		status = "disabled";
	};

	/* USI01_USI */
	spi_1: spi@10570000 {
		compatible = "samsung,exynos-spi";
		samsung,spi-fifosize = <64>;
		swap-mode = <1>;
		#address-cells = <1>;
		#size-cells = <0>;
/*
		dma-mode;
		dmas = <&pdma0 3 &pdma0 2>;
*/
		dma-names = "tx", "rx";
		interrupts = <GIC_SPI INTREQ__USI01_USI IRQ_TYPE_LEVEL_HIGH>;
		samsung,usi-phandle = <&sysreg_peric0_usi>;
		clocks = <&clock GATE_PERIC0_TOP0_QCH_USI01_USI>, <&clock DOUT_DIV_CLK_PERIC0_USI01_USI>;
		clock-names = "gate_spi_clk", "ipclk_spi";
		pinctrl-names = "default";
		pinctrl-0 = <&spi1_bus>;
		samsung,usi-offset = <0x0c>;
		reg = <0x0 0x10570000 0x1000>;
		status = "disabled";
	};

	/* USI02_USI */
	spi_2: spi@10590000 {
		compatible = "samsung,exynos-spi";
		samsung,spi-fifosize = <64>;
		swap-mode = <1>;
		#address-cells = <1>;
		#size-cells = <0>;
/*
		dma-mode;
		dmas = <&pdma0 5 &pdma0 4>;
*/
		dma-names = "tx", "rx";
		interrupts = <GIC_SPI INTREQ__USI02_USI IRQ_TYPE_LEVEL_HIGH>;
		samsung,usi-phandle = <&sysreg_peric0_usi>;
		clocks = <&clock GATE_PERIC0_TOP0_QCH_USI02_USI>, <&clock DOUT_DIV_CLK_PERIC0_USI02_USI>;
		clock-names = "gate_spi_clk", "ipclk_spi";
		pinctrl-names = "default";
		pinctrl-0 = <&spi2_bus>;
		samsung,usi-offset = <0x14>;
		reg = <0x0 0x10590000 0x1000>;
		status = "disabled";
	};

	/* USI03_USI */
	spi_3: spi@105B0000 {
		compatible = "samsung,exynos-spi";
		samsung,spi-fifosize = <64>;
		swap-mode = <1>;
		#address-cells = <1>;
		#size-cells = <0>;
/*
		dma-mode;
		dmas = <&pdma0 7 &pdma0 6>;
*/
		dma-names = "tx", "rx";
		interrupts = <GIC_SPI INTREQ__USI03_USI IRQ_TYPE_LEVEL_HIGH>;
		samsung,usi-phandle = <&sysreg_peric0_usi>;
		clocks = <&clock GATE_PERIC0_TOP0_QCH_USI03_USI>, <&clock DOUT_DIV_CLK_PERIC0_USI03_USI>;
		clock-names = "gate_spi_clk", "ipclk_spi";
		pinctrl-names = "default";
		pinctrl-0 = <&spi3_bus>;
		samsung,usi-offset = <0x1c>;
		reg = <0x0 0x105b0000 0x1000>;
		status = "disabled";
	};

	/* USI04_USI */
	spi_4: spi@105D0000 {
		compatible = "samsung,exynos-spi";
		samsung,spi-fifosize = <64>;
		swap-mode = <1>;
		#address-cells = <1>;
		#size-cells = <0>;
/*
		dma-mode;
		dmas = <&pdma0 9 &pdma0 8>;
*/
		dma-names = "tx", "rx";
		interrupts = <GIC_SPI INTREQ__USI04_USI IRQ_TYPE_LEVEL_HIGH>;
		samsung,usi-phandle = <&sysreg_peric0_usi>;
		clocks = <&clock GATE_PERIC0_TOP0_QCH_USI04_USI>, <&clock DOUT_DIV_CLK_PERIC0_USI04_USI>;
		clock-names = "gate_spi_clk", "ipclk_spi";
		pinctrl-names = "default";
		pinctrl-0 = <&spi4_bus>;
		samsung,usi-offset = <0x24>;
		reg = <0x0 0x105d0000 0x1000>;
		status = "disabled";
	};

	/* USI05_USI */
	spi_5: spi@105F0000 {
		compatible = "samsung,exynos-spi";
		samsung,spi-fifosize = <64>;
		swap-mode = <1>;
		#address-cells = <1>;
		#size-cells = <0>;
/*
		dma-mode;
		dmas = <&pdma0 11 &pdma0 10>;
*/
		dma-names = "tx", "rx";
		interrupts = <GIC_SPI INTREQ__USI05_USI IRQ_TYPE_LEVEL_HIGH>;
		samsung,usi-phandle = <&sysreg_peric0_usi>;
		clocks = <&clock GATE_PERIC0_TOP0_QCH_USI05_USI>, <&clock DOUT_DIV_CLK_PERIC0_USI05_USI>;
		clock-names = "gate_spi_clk", "ipclk_spi";
		pinctrl-names = "default";
		pinctrl-0 = <&spi5_bus>;
		samsung,usi-offset = <0x2c>;
		reg = <0x0 0x105f0000 0x1000>;
		status = "disabled";
	};

	/* USI06_USI */
	spi_6: spi@11EA0000 {
		compatible = "samsung,exynos-spi";
		samsung,spi-fifosize = <64>;
		swap-mode = <1>;
		#address-cells = <1>;
		#size-cells = <0>;
/*
		dma-mode;
		dmas = <&pdma0 15 &pdma0 14>;
*/
		dma-names = "tx", "rx";
		interrupts = <GIC_SPI INTREQ__USI06_USI IRQ_TYPE_LEVEL_HIGH>;
		samsung,usi-phandle = <&sysreg_peric2_usi>;
		clocks = <&clock GATE_PERIC2_TOP0_QCH_USI06_USI>, <&clock DOUT_DIV_CLK_PERIC2_USI06_USI>;
		clock-names = "gate_spi_clk", "ipclk_spi";
		pinctrl-names = "default";
		pinctrl-0 = <&spi6_bus>;
		samsung,usi-offset = <0x00>;
		reg = <0x0 0x11ea0000 0x1000>;
		status = "disabled";
	};

	/* USI07_USI */
	spi_7: spi@11EC0000 {
		compatible = "samsung,exynos-spi";
		samsung,spi-fifosize = <64>;
		swap-mode = <1>;
		#address-cells = <1>;
		#size-cells = <0>;
/*
		dma-mode;
		dmas = <&pdma0 17 &pdma0 16>;
*/
		dma-names = "tx", "rx";
		interrupts = <GIC_SPI INTREQ__USI07_USI IRQ_TYPE_LEVEL_HIGH>;
		samsung,usi-phandle = <&sysreg_peric2_usi>;
		clocks = <&clock GATE_PERIC2_TOP0_QCH_USI07_USI>, <&clock DOUT_DIV_CLK_PERIC2_USI07_USI>;
		clock-names = "gate_spi_clk", "ipclk_spi";
		pinctrl-names = "default";
		pinctrl-0 = <&spi7_bus>;
		samsung,usi-offset = <0x08>;
		reg = <0x0 0x11ec0000 0x1000>;
		status = "disabled";
	};

	/* USI08_USI */
	spi_8: spi@11EE0000 {
		compatible = "samsung,exynos-spi";
		samsung,spi-fifosize = <256>;
		swap-mode = <1>;
		#address-cells = <1>;
		#size-cells = <0>;
/*
		dma-mode;
		dmas = <&pdma0 19 &pdma0 18>;
*/
		dma-names = "tx", "rx";
		interrupts = <GIC_SPI INTREQ__USI08_USI IRQ_TYPE_LEVEL_HIGH>;
		samsung,usi-phandle = <&sysreg_peric2_usi>;
		clocks = <&clock GATE_PERIC2_TOP0_QCH_USI08_USI>, <&clock DOUT_DIV_CLK_PERIC2_USI08_USI>;
		clock-names = "gate_spi_clk", "ipclk_spi";
		pinctrl-names = "default";
		pinctrl-0 = <&spi8_bus>;
		samsung,usi-offset = <0x10>;
		reg = <0x0 0x11ee0000 0x1000>;
		status = "disabled";
	};

	/* USI09_USI */
	spi_9: spi@11f00000 {
		compatible = "samsung,exynos-spi";
		samsung,spi-fifosize = <256>;
		swap-mode = <1>;
		#address-cells = <1>;
		#size-cells = <0>;
/*
		dma-mode;
		dmas = <&pdma0 21 &pdma0 20>;
*/
		dma-names = "tx", "rx";
		interrupts = <GIC_SPI INTREQ__USI09_USI IRQ_TYPE_LEVEL_HIGH>;
		samsung,usi-phandle = <&sysreg_peric2_usi>;
		clocks = <&clock GATE_PERIC2_TOP1_QCH_USI09_USI>, <&clock DOUT_DIV_CLK_PERIC2_USI09_USI>;
		clock-names = "gate_spi_clk", "ipclk_spi";
		pinctrl-names = "default";
		pinctrl-0 = <&spi9_bus>;
		samsung,usi-offset = <0x18>;
		reg = <0x0 0x11f00000 0x1000>;
		status = "disabled";
	};

	/* USI10_USI */
	spi_10: spi@11f20000 {
		compatible = "samsung,exynos-spi";
		samsung,spi-fifosize = <256>;
		swap-mode = <1>;
		#address-cells = <1>;
		#size-cells = <0>;
/*
		dma-mode;
		dmas = <&pdma0 23 &pdma0 22>;
*/
		dma-names = "tx", "rx";
		interrupts = <GIC_SPI INTREQ__USI10_USI IRQ_TYPE_LEVEL_HIGH>;
		samsung,usi-phandle = <&sysreg_peric2_usi>;
		clocks = <&clock GATE_PERIC2_TOP1_QCH_USI10_USI>, <&clock DOUT_DIV_CLK_PERIC2_USI10_USI>;
		clock-names = "gate_spi_clk", "ipclk_spi";
		pinctrl-names = "default";
		pinctrl-0 = <&spi10_bus>;
		samsung,usi-offset = <0x20>;
		reg = <0x0 0x11f20000 0x1000>;
		status = "disabled";
	};

	/* USI11_USI */
	spi_11: spi@10940000 {
		compatible = "samsung,exynos-spi";
		samsung,spi-fifosize = <64>;
		swap-mode = <1>;
		#address-cells = <1>;
		#size-cells = <0>;
/*
		dma-mode;
		dmas = <&pdma0 25 &pdma0 24>;
*/
		dma-names = "tx", "rx";
		interrupts = <GIC_SPI INTREQ__USI11_USI IRQ_TYPE_LEVEL_HIGH>;
		samsung,usi-phandle = <&sysreg_peric1_1_usi>;
		clocks = <&clock GATE_PERIC1_TOP1_QCH_USI11_USI>, <&clock DOUT_DIV_CLK_PERIC1_USI11_USI>;
		clock-names = "gate_spi_clk", "ipclk_spi";
		pinctrl-names = "default";
		pinctrl-0 = <&spi11_bus>;
		samsung,usi-offset = <0x28>;
		reg = <0x0 0x10940000 0x1000>;
		status = "disabled";
	};

	/* USI12_USI */
	spi_12: spi@109C0000 {
		compatible = "samsung,exynos-spi";
		samsung,spi-fifosize = <64>;
		swap-mode = <1>;
		#address-cells = <1>;
		#size-cells = <0>;
/*
		dma-mode;
		dmas = <&pdma0 31 &pdma0 30>;
*/
		dma-names = "tx", "rx";
		interrupts = <GIC_SPI INTREQ__USI12_USI IRQ_TYPE_LEVEL_HIGH>;
		samsung,usi-phandle = <&sysreg_peric1_2_usi>;
		clocks = <&clock GATE_PERIC1_TOP1_QCH_USI12_USI>, <&clock DOUT_DIV_CLK_PERIC1_USI12_USI>;
		clock-names = "gate_spi_clk", "ipclk_spi";
		pinctrl-names = "default";
		pinctrl-0 = <&spi12_bus>;
		samsung,usi-offset = <0x00>;
		reg = <0x0 0x109c0000 0x1000>;
		status = "disabled";
	};

	/* USI13_USI */
	spi_13: spi@10630000 {
		compatible = "samsung,exynos-spi";
		samsung,spi-fifosize = <64>;
		swap-mode = <1>;
		#address-cells = <1>;
		#size-cells = <0>;
		interrupts = <GIC_SPI INTREQ__USI13_USI IRQ_TYPE_LEVEL_HIGH>;
		samsung,usi-phandle = <&sysreg_peric0_usi>;
		clocks = <&clock GATE_PERIC0_TOP1_QCH_USI13_USI>, <&clock DOUT_DIV_CLK_PERIC0_USI13_USI>;
		clock-names = "gate_spi_clk", "ipclk_spi";
		pinctrl-names = "default";
		pinctrl-0 = <&spi13_bus>;
		samsung,usi-offset = <0x3c>;
		reg = <0x0 0x10630000 0x1000>;
		status = "disabled";
	};

	/* USI14_USI */
	spi_14: spi@10650000 {
		compatible = "samsung,exynos-spi";
		samsung,spi-fifosize = <64>;
		swap-mode = <1>;
		#address-cells = <1>;
		#size-cells = <0>;
		interrupts = <GIC_SPI INTREQ__USI14_USI IRQ_TYPE_LEVEL_HIGH>;
		samsung,usi-phandle = <&sysreg_peric0_usi>;
		clocks = <&clock GATE_PERIC0_TOP1_QCH_USI14_USI>, <&clock DOUT_DIV_CLK_PERIC0_USI14_USI>;
		clock-names = "gate_spi_clk", "ipclk_spi";
		pinctrl-names = "default";
		pinctrl-0 = <&spi14_bus>;
		samsung,usi-offset = <0x44>;
		reg = <0x0 0x10650000 0x1000>;
		status = "disabled";
	};

	/* USI15_USI */
	spi_15: spi@10670000 {
		compatible = "samsung,exynos-spi";
		samsung,spi-fifosize = <64>;
		swap-mode = <1>;
		#address-cells = <1>;
		#size-cells = <0>;
		interrupts = <GIC_SPI INTREQ__USI15_USI IRQ_TYPE_LEVEL_HIGH>;
		samsung,usi-phandle = <&sysreg_peric0_usi>;
		clocks = <&clock GATE_PERIC0_TOP1_QCH_USI15_USI>, <&clock DOUT_DIV_CLK_PERIC0_USI15_USI>;
		clock-names = "gate_spi_clk", "ipclk_spi";
		pinctrl-names = "default";
		pinctrl-0 = <&spi15_bus>;
		samsung,usi-offset = <0x4c>;
		reg = <0x0 0x10670000 0x1000>;
		status = "disabled";
	};

	/* USI16_USI */
	spi_16: spi@10960000 {
		compatible = "samsung,exynos-spi";
		samsung,spi-fifosize = <64>;
		swap-mode = <1>;
		#address-cells = <1>;
		#size-cells = <0>;
/*
		dma-mode;
		dmas = <&pdma0 19 &pdma0 18>;
*/
		dma-names = "tx", "rx";
		interrupts = <GIC_SPI INTREQ__USI16_USI IRQ_TYPE_LEVEL_HIGH>;
		samsung,usi-phandle = <&sysreg_peric1_1_usi>;
		clocks = <&clock GATE_PERIC1_TOP1_QCH_USI16_USI>, <&clock DOUT_DIV_CLK_PERIC1_USI16_USI>;
		clock-names = "gate_spi_clk", "ipclk_spi";
		pinctrl-names = "default";
		pinctrl-0 = <&spi16_bus>;
		samsung,usi-offset = <0x30>;
		reg = <0x0 0x10960000 0x1000>;
		status = "disabled";
	};

	/* USI17_USI */
	spi_17: spi@10990000 {
		compatible = "samsung,exynos-spi";
		samsung,spi-fifosize = <64>;
		swap-mode = <1>;
		#address-cells = <1>;
		#size-cells = <0>;
/*
		dma-mode;
		dmas = <&pdma0 21 &pdma0 20>;
*/
		dma-names = "tx", "rx";
		interrupts = <GIC_SPI INTREQ__USI17_USI IRQ_TYPE_LEVEL_HIGH>;
		samsung,usi-phandle = <&sysreg_peric1_1_usi>;
		clocks = <&clock GATE_PERIC1_TOP1_QCH_USI17_USI>, <&clock DOUT_DIV_CLK_PERIC1_USI17_USI>;
		clock-names = "gate_spi_clk", "ipclk_spi";
		pinctrl-names = "default";
		pinctrl-0 = <&spi17_bus>;
		samsung,usi-offset = <0x38>;
		reg = <0x0 0x10990000 0x1000>;
		status = "disabled";
	};

	/* USI18_USI */
	spi_18: spi@109E0000 {
		compatible = "samsung,exynos-spi";
		samsung,spi-fifosize = <64>;
		swap-mode = <1>;
		#address-cells = <1>;
		#size-cells = <0>;
/*
		dma-mode;
		dmas = <&pdma0 25 &pdma0 24>;
*/
		dma-names = "tx", "rx";
		interrupts = <GIC_SPI INTREQ__USI18_USI IRQ_TYPE_LEVEL_HIGH>;
		samsung,usi-phandle = <&sysreg_peric1_2_usi>;
		clocks = <&clock GATE_PERIC1_TOP1_QCH_USI18_USI>, <&clock DOUT_DIV_CLK_PERIC1_USI18_USI>;
		clock-names = "gate_spi_clk", "ipclk_spi";
		pinctrl-names = "default";
		pinctrl-0 = <&spi18_bus>;
		samsung,usi-offset = <0x08>;
		reg = <0x0 0x109e0000 0x1000>;
		status = "disabled";
	};

	/* USI_CMGP00 */
	spi_19: spi@14F00000 {
		compatible = "samsung,exynos-spi";
		samsung,spi-fifosize = <64>;
		swap-mode = <1>;
		#address-cells = <1>;
		#size-cells = <0>;
		interrupts = <GIC_SPI INTREQ__USI_CMGP0 IRQ_TYPE_LEVEL_HIGH>;
		samsung,usi-phandle = <&sysreg_cmgp_usi>;
		clocks = <&clock GATE_USI_CMGP0_QCH>, <&clock DOUT_DIV_CLK_CMGP_USI0>;
		clock-names = "gate_spi_clk", "ipclk_spi";
		pinctrl-names = "default";
		pinctrl-0 = <&spi19_bus>;
		samsung,usi-offset = <0x00>;
		reg = <0x0 0x14f00000 0x1000>;
		status = "disabled";
	};

	/* USI_CMGP01 */
	spi_20: spi@14F20000 {
		compatible = "samsung,exynos-spi";
		samsung,spi-fifosize = <64>;
		swap-mode = <1>;
		#address-cells = <1>;
		#size-cells = <0>;
		interrupts = <GIC_SPI INTREQ__USI_CMGP1 IRQ_TYPE_LEVEL_HIGH>;
		samsung,usi-phandle = <&sysreg_cmgp_usi>;
		clocks = <&clock GATE_USI_CMGP1_QCH>, <&clock DOUT_DIV_CLK_CMGP_USI1>;
		clock-names = "gate_spi_clk", "ipclk_spi";
		pinctrl-names = "default";
		pinctrl-0 = <&spi20_bus>;
		samsung,usi-offset = <0x10>;
		reg = <0x0 0x14f20000 0x1000>;
		status = "disabled";
	};

	/* USI_CMGP02 */
	spi_21: spi@14F40000 {
		compatible = "samsung,exynos-spi";
		samsung,spi-fifosize = <64>;
		swap-mode = <1>;
		#address-cells = <1>;
		#size-cells = <0>;
		interrupts = <GIC_SPI INTREQ__USI_CMGP2 IRQ_TYPE_LEVEL_HIGH>;
		samsung,usi-phandle = <&sysreg_cmgp_usi>;
		clocks = <&clock GATE_USI_CMGP2_QCH>, <&clock DOUT_DIV_CLK_CMGP_USI2>;
		clock-names = "gate_spi_clk", "ipclk_spi";
		pinctrl-names = "default";
		pinctrl-0 = <&spi21_bus>;
		samsung,usi-offset = <0x20>;
		reg = <0x0 0x14f40000 0x1000>;
		status = "disabled";
	};

	/* USI_CMGP03 */
	spi_22: spi@14F60000 {
		compatible = "samsung,exynos-spi";
		samsung,spi-fifosize = <64>;
		swap-mode = <1>;
		#address-cells = <1>;
		#size-cells = <0>;
		interrupts = <GIC_SPI INTREQ__USI_CMGP3 IRQ_TYPE_LEVEL_HIGH>;
		samsung,usi-phandle = <&sysreg_cmgp_usi>;
		clocks = <&clock GATE_USI_CMGP3_QCH>, <&clock DOUT_DIV_CLK_CMGP_USI3>;
		clock-names = "gate_spi_clk", "ipclk_spi";
		pinctrl-names = "default";
		pinctrl-0 = <&spi22_bus>;
		samsung,usi-offset = <0x30>;
		reg = <0x0 0x14f60000 0x1000>;
		status = "disabled";
	};

	/* USI_PERIC0_UART_DBG */
	serial_0: uart@10540000 {
		compatible = "samsung,exynos-uart";
		samsung,separate-uart-clk;
		reg = <0x0 0x10540000 0x100>;
		samsung,fifo-size = <256>;
		reg-io-width = <4>;
		interrupts = <GIC_SPI INTREQ__DBG_UART IRQ_TYPE_LEVEL_HIGH>;
		pinctrl-names = "default";
		pinctrl-0 = <&uart0_bus>;
		samsung,usi-serial-v2;
		clocks = <&clock GATE_PERIC0_TOP0_QCH_UART_DBG>, <&clock UART_DBG>;
		clock-names = "gate_uart_clk0", "ipclk_uart0";
		samsung,usi-phandle = <&sysreg_peric0_usi>;
		samsung,usi-offset = <0x00>;
		samsung,dbg-uart-ch;
		samsung,dbg-uart-baud = <115200>;
		samsung,dbg-word-len = <8>;
		samsung,source-clock-rate = <133333333>;
		status = "disabled";
	};

	/* USI_PERIC1_UART_BT */
	serial_1: uart@10840000 {
		compatible = "samsung,exynos-uart";
		samsung,separate-uart-clk;
		reg = <0x0 0x10840000 0x100>;
		samsung,fifo-size = <256>;
		interrupts = <GIC_SPI INTREQ__BT_UART IRQ_TYPE_LEVEL_HIGH>;
		pinctrl-names = "default", "rts", "tx_dat";
		pinctrl-0 = <&uart1_bus_single>; /* or _bus_dual */
		pinctrl-1 = <&uart1_bus_rts &uart1_bus_tx_con>;
		pinctrl-2 = <&uart1_bus_tx_dat>;
		samsung,usi-serial-v2;
		clocks = <&clock GATE_PERIC1_TOP0_QCH_UART_BT>, <&clock DOUT_DIV_CLK_PERIC1_UART_BT>;
		clock-names = "gate_uart_clk1", "ipclk_uart1";
		samsung,usi-phandle = <&sysreg_peric1_1_usi>;
		samsung,usi-offset = <0x00>;
		status = "disabled";
	};

	/* USI_PERIC0_USI00_UART */
	serial_2: uart@10550000 {
		compatible = "samsung,exynos-uart";
		samsung,separate-uart-clk;
		reg = <0x0 0x10550000 0x100>;
		samsung,fifo-size = <64>;
		interrupts = <GIC_SPI INTREQ__USI00_USI IRQ_TYPE_LEVEL_HIGH>;
		pinctrl-names = "default";
		pinctrl-0 = <&uart2_bus_single>; /* or _bus_dual */
		samsung,usi-serial-v2;
		clocks = <&clock GATE_PERIC0_TOP0_QCH_USI00_USI>, <&clock DOUT_DIV_CLK_PERIC0_USI00_USI>;
		clock-names = "gate_uart_clk2", "ipclk_uart2";
		samsung,usi-phandle = <&sysreg_peric0_usi>;
		samsung,usi-offset = <0x04>;
		status = "disabled";
	};

	/* USI_PERIC0_USI01_UART */
	serial_3: uart@10570000 {
		compatible = "samsung,exynos-uart";
		samsung,separate-uart-clk;
		reg = <0x0 0x10570000 0x100>;
		samsung,fifo-size = <64>;
		interrupts = <GIC_SPI INTREQ__USI01_USI IRQ_TYPE_LEVEL_HIGH>;
		pinctrl-names = "default";
		pinctrl-0 = <&uart3_bus_single>; /* or _bus_dual */
		samsung,usi-serial-v2;
		clocks = <&clock GATE_PERIC0_TOP0_QCH_USI01_USI>, <&clock DOUT_DIV_CLK_PERIC0_USI01_USI>;
		clock-names = "gate_uart_clk3", "ipclk_uart3";
		samsung,usi-phandle = <&sysreg_peric0_usi>;
		samsung,usi-offset = <0x0c>;
		status = "disabled";
	};

	/* USI_PERIC0_USI02_UART */
	serial_4: uart@10590000 {
		compatible = "samsung,exynos-uart";
		samsung,separate-uart-clk;
		reg = <0x0 0x10590000 0x100>;
		samsung,fifo-size = <64>;
		interrupts = <GIC_SPI INTREQ__USI02_USI IRQ_TYPE_LEVEL_HIGH>;
		pinctrl-names = "default";
		pinctrl-0 = <&uart4_bus_single>; /* or _bus_dual */
		samsung,usi-serial-v2;
		clocks = <&clock GATE_PERIC0_TOP0_QCH_USI02_USI>, <&clock DOUT_DIV_CLK_PERIC0_USI02_USI>;
		clock-names = "gate_uart_clk4", "ipclk_uart4";
		samsung,usi-phandle = <&sysreg_peric0_usi>;
		samsung,usi-offset = <0x14>;
		status = "disabled";
	};

	/* USI_PERIC0_USI03_UART */
	serial_5: uart@105B0000 {
		compatible = "samsung,exynos-uart";
		samsung,separate-uart-clk;
		reg = <0x0 0x105B0000 0x100>;
		samsung,fifo-size = <64>;
		interrupts = <GIC_SPI INTREQ__USI03_USI IRQ_TYPE_LEVEL_HIGH>;
		pinctrl-names = "default";
		pinctrl-0 = <&uart5_bus_single>; /* or _bus_dual */
		samsung,usi-serial-v2;
		clocks = <&clock GATE_PERIC0_TOP0_QCH_USI03_USI>, <&clock DOUT_DIV_CLK_PERIC0_USI03_USI>;
		clock-names = "gate_uart_clk5", "ipclk_uart5";
		samsung,usi-phandle = <&sysreg_peric0_usi>;
		samsung,usi-offset = <0x1c>;
		status = "disabled";
	};

	/* USI_PERIC0_USI04_UART */
	serial_6: uart@105D0000 {
		compatible = "samsung,exynos-uart";
		samsung,separate-uart-clk;
		reg = <0x0 0x105D0000 0x100>;
		samsung,fifo-size = <64>;
		interrupts = <GIC_SPI INTREQ__USI04_USI IRQ_TYPE_LEVEL_HIGH>;
		pinctrl-names = "default";
		pinctrl-0 = <&uart6_bus_single>; /* or _bus_dual */
		samsung,usi-serial-v2;
		clocks = <&clock GATE_PERIC0_TOP0_QCH_USI04_USI>, <&clock DOUT_DIV_CLK_PERIC0_USI04_USI>;
		clock-names = "gate_uart_clk6", "ipclk_uart6";
		samsung,usi-phandle = <&sysreg_peric0_usi>;
		samsung,usi-offset = <0x24>;
		status = "disabled";
	};

	/* USI_PERIC0_USI05_UART */
	serial_7: uart@105F0000 {
		compatible = "samsung,exynos-uart";
		samsung,separate-uart-clk;
		reg = <0x0 0x105F0000 0x100>;
		samsung,fifo-size = <64>;
		interrupts = <GIC_SPI INTREQ__USI05_USI IRQ_TYPE_LEVEL_HIGH>;
		pinctrl-names = "default";
		pinctrl-0 = <&uart7_bus_single>; /* or _bus_dual */
		samsung,usi-serial-v2;
		clocks = <&clock GATE_PERIC0_TOP0_QCH_USI05_USI>, <&clock DOUT_DIV_CLK_PERIC0_USI05_USI>;
		clock-names = "gate_uart_clk7", "ipclk_uart7";
		samsung,usi-phandle = <&sysreg_peric0_usi>;
		samsung,usi-offset = <0x2c>;
		status = "disabled";
	};

	/* USI_PERIC2_USI06_UART */
	serial_8: uart@11EA0000 {
		compatible = "samsung,exynos-uart";
		samsung,separate-uart-clk;
		reg = <0x0 0x11EA0000 0x100>;
		samsung,fifo-size = <64>;
		interrupts = <GIC_SPI INTREQ__USI06_USI IRQ_TYPE_LEVEL_HIGH>;
		pinctrl-names = "default";
		pinctrl-0 = <&uart8_bus_single>; /* or _bus_dual */
		samsung,usi-serial-v2;
		clocks = <&clock GATE_PERIC2_TOP0_QCH_USI06_USI>, <&clock DOUT_DIV_CLK_PERIC2_USI06_USI>;
		clock-names = "gate_uart_clk8", "ipclk_uart8";
		samsung,usi-phandle = <&sysreg_peric2_usi>;
		samsung,usi-offset = <0x00>;
		status = "disabled";
	};

	/* USI_PERIC2_USI07_UART */
	serial_9: uart@11EC0000 {
		compatible = "samsung,exynos-uart";
		samsung,separate-uart-clk;
		reg = <0x0 0x11EC0000 0x100>;
		samsung,fifo-size = <64>;
		interrupts = <GIC_SPI INTREQ__USI07_USI IRQ_TYPE_LEVEL_HIGH>;
		pinctrl-names = "default";
		pinctrl-0 = <&uart9_bus_single>; /* or _bus_dual */
		samsung,usi-serial-v2;
		clocks = <&clock GATE_PERIC2_TOP0_QCH_USI07_USI>, <&clock DOUT_DIV_CLK_PERIC2_USI07_USI>;
		clock-names = "gate_uart_clk9", "ipclk_uart9";
		samsung,usi-phandle = <&sysreg_peric2_usi>;
		samsung,usi-offset = <0x08>;
		status = "disabled";
	};

	/* USI_PERIC2_USI08_UART */
	serial_10: uart@11EE0000 {
		compatible = "samsung,exynos-uart";
		samsung,separate-uart-clk;
		reg = <0x0 0x11EE0000 0x100>;
		samsung,fifo-size = <256>;
		interrupts = <GIC_SPI INTREQ__USI08_USI IRQ_TYPE_LEVEL_HIGH>;
		pinctrl-names = "default";
		pinctrl-0 = <&uart10_bus_single>; /* or _bus_dual */
		samsung,usi-serial-v2;
		clocks = <&clock GATE_PERIC2_TOP0_QCH_USI08_USI>, <&clock DOUT_DIV_CLK_PERIC2_USI08_USI>;
		clock-names = "gate_uart_clk10", "ipclk_uart10";
		samsung,usi-phandle = <&sysreg_peric2_usi>;
		samsung,usi-offset = <0x10>;
		status = "disabled";
	};

	/* USI_PERIC1_USI09_UART */
	serial_11: uart@11f00000 {
		compatible = "samsung,exynos-uart";
		samsung,separate-uart-clk;
		reg = <0x0 0x11f00000 0x100>;
		samsung,fifo-size = <256>;
		interrupts = <GIC_SPI INTREQ__USI09_USI IRQ_TYPE_LEVEL_HIGH>;
		pinctrl-names = "default";
		pinctrl-0 = <&uart11_bus_single>; /* or _bus_dual */
		samsung,usi-serial-v2;
		clocks = <&clock GATE_PERIC2_TOP1_QCH_USI09_USI>, <&clock DOUT_DIV_CLK_PERIC2_USI09_USI>;
		clock-names = "gate_uart_clk11", "ipclk_uart11";
		samsung,usi-phandle = <&sysreg_peric2_usi>;
		samsung,usi-offset = <0x18>;
		status = "disabled";
	};

	/* USI_PERIC1_USI10_UART */
	serial_12: uart@11f20000 {
		compatible = "samsung,exynos-uart";
		samsung,separate-uart-clk;
		reg = <0x0 0x11f20000 0x100>;
		samsung,fifo-size = <256>;
		interrupts = <GIC_SPI INTREQ__USI10_USI IRQ_TYPE_LEVEL_HIGH>;
		pinctrl-names = "default";
		pinctrl-0 = <&uart12_bus_single>; /* or _bus_dual */
		samsung,usi-serial-v2;
		clocks = <&clock GATE_PERIC2_TOP1_QCH_USI10_USI>, <&clock DOUT_DIV_CLK_PERIC2_USI10_USI>;
		clock-names = "gate_uart_clk12", "ipclk_uart12";
		samsung,usi-phandle = <&sysreg_peric2_usi>;
		samsung,usi-offset = <0x20>;
		status = "disabled";
	};

	/* USI_PERIC1_USI11_UART */
	serial_13: uart@10940000 {
		compatible = "samsung,exynos-uart";
		samsung,separate-uart-clk;
		reg = <0x0 0x10940000 0x100>;
		samsung,fifo-size = <64>;
		interrupts = <GIC_SPI INTREQ__USI11_USI IRQ_TYPE_LEVEL_HIGH>;
		pinctrl-names = "default";
		pinctrl-0 = <&uart13_bus_single>; /* or _bus_dual */
		samsung,usi-serial-v2;
		clocks = <&clock GATE_PERIC1_TOP1_QCH_USI11_USI>, <&clock DOUT_DIV_CLK_PERIC1_USI11_USI>;
		clock-names = "gate_uart_clk13", "ipclk_uart13";
		samsung,usi-phandle = <&sysreg_peric1_1_usi>;
		samsung,usi-offset = <0x28>;
		status = "disabled";
	};

	/* USI_PERIC1_USI12_UART */
	serial_14: uart@109C0000 {
		compatible = "samsung,exynos-uart";
		samsung,separate-uart-clk;
		reg = <0x0 0x109C0000 0x100>;
		samsung,fifo-size = <64>;
		interrupts = <GIC_SPI INTREQ__USI12_USI IRQ_TYPE_LEVEL_HIGH>;
		pinctrl-names = "default";
		pinctrl-0 = <&uart14_bus_single>; /* or _bus_dual */
		samsung,usi-serial-v2;
		clocks = <&clock GATE_PERIC1_TOP1_QCH_USI12_USI>, <&clock DOUT_DIV_CLK_PERIC1_USI12_USI>;
		clock-names = "gate_uart_clk14", "ipclk_uart14";
		samsung,usi-phandle = <&sysreg_peric1_2_usi>;
		samsung,usi-offset = <0x00>;
		status = "disabled";
	};

	/* USI_PERIC0_USI13_UART */
	serial_15: uart@10630000 {
		compatible = "samsung,exynos-uart";
		samsung,separate-uart-clk;
		reg = <0x0 0x10630000 0x100>;
		samsung,fifo-size = <64>;
		interrupts = <GIC_SPI INTREQ__USI13_USI IRQ_TYPE_LEVEL_HIGH>;
		pinctrl-names = "default";
		pinctrl-0 = <&uart15_bus_single>; /* or _bus_dual */
		samsung,usi-serial-v2;
		clocks = <&clock GATE_PERIC0_TOP1_QCH_USI13_USI>, <&clock DOUT_DIV_CLK_PERIC0_USI13_USI>;
		clock-names = "gate_uart_clk15", "ipclk_uart15";
		samsung,usi-phandle = <&sysreg_peric0_usi>;
		samsung,usi-offset = <0x3c>;
		status = "disabled";
	};

	/* USI_PERIC0_USI14_UART */
	serial_16: uart@10650000 {
		compatible = "samsung,exynos-uart";
		samsung,separate-uart-clk;
		reg = <0x0 0x10650000 0x100>;
		samsung,fifo-size = <64>;
		interrupts = <GIC_SPI INTREQ__USI14_USI IRQ_TYPE_LEVEL_HIGH>;
		pinctrl-names = "default";
		pinctrl-0 = <&uart16_bus_single>; /* or _bus_dual */
		samsung,usi-serial-v2;
		clocks = <&clock GATE_PERIC0_TOP1_QCH_USI14_USI>, <&clock DOUT_DIV_CLK_PERIC0_USI14_USI>;
		clock-names = "gate_uart_clk16", "ipclk_uart16";
		samsung,usi-phandle = <&sysreg_peric0_usi>;
		samsung,usi-offset = <0x44>;
		status = "disabled";
	};

	/* USI_PERIC0_USI15_UART */
	serial_17: uart@10670000 {
		compatible = "samsung,exynos-uart";
		samsung,separate-uart-clk;
		reg = <0x0 0x10670000 0x100>;
		samsung,fifo-size = <64>;
		interrupts = <GIC_SPI INTREQ__USI15_USI IRQ_TYPE_LEVEL_HIGH>;
		pinctrl-names = "default";
		pinctrl-0 = <&uart17_bus_single>; /* or _bus_dual */
		samsung,usi-serial-v2;
		clocks = <&clock GATE_PERIC0_TOP1_QCH_USI15_USI>, <&clock DOUT_DIV_CLK_PERIC0_USI15_USI>;
		clock-names = "gate_uart_clk17", "ipclk_uart17";
		samsung,usi-phandle = <&sysreg_peric0_usi>;
		samsung,usi-offset = <0x4c>;
		status = "disabled";
	};

	/* USI_PERIC1_USI16_UART */
	serial_18: uart@10960000 {
		compatible = "samsung,exynos-uart";
		samsung,separate-uart-clk;
		reg = <0x0 0x10960000 0x100>;
		samsung,fifo-size = <64>;
		interrupts = <GIC_SPI INTREQ__USI16_USI IRQ_TYPE_LEVEL_HIGH>;
		pinctrl-names = "default";
		pinctrl-0 = <&uart18_bus_single>; /* or _bus_dual */
		samsung,usi-serial-v2;
		clocks = <&clock GATE_PERIC1_TOP1_QCH_USI16_USI>, <&clock DOUT_DIV_CLK_PERIC1_USI16_USI>;
		clock-names = "gate_uart_clk18", "ipclk_uart18";
		samsung,usi-phandle = <&sysreg_peric1_1_usi>;
		samsung,usi-offset = <0x30>;
		status = "disabled";
	};

	/* USI_PERIC1_USI17_UART */
	serial_19: uart@10990000 {
		compatible = "samsung,exynos-uart";
		samsung,separate-uart-clk;
		reg = <0x0 0x10990000 0x100>;
		samsung,fifo-size = <64>;
		interrupts = <GIC_SPI INTREQ__USI17_USI IRQ_TYPE_LEVEL_HIGH>;
		pinctrl-names = "default";
		pinctrl-0 = <&uart19_bus_single>; /* or _bus_dual */
		samsung,usi-serial-v2;
		clocks = <&clock GATE_PERIC1_TOP1_QCH_USI17_USI>, <&clock DOUT_DIV_CLK_PERIC1_USI17_USI>;
		clock-names = "gate_uart_clk19", "ipclk_uart19";
		samsung,usi-phandle = <&sysreg_peric1_1_usi>;
		samsung,usi-offset = <0x38>;
		status = "disabled";
	};

	/* USI_PERIC1_USI18_UART */
	serial_20: uart@109E0000 {
		compatible = "samsung,exynos-uart";
		samsung,separate-uart-clk;
		reg = <0x0 0x109E0000 0x100>;
		samsung,fifo-size = <64>;
		interrupts = <GIC_SPI INTREQ__USI18_USI IRQ_TYPE_LEVEL_HIGH>;
		pinctrl-names = "default";
		pinctrl-0 = <&uart20_bus_single>; /* or _bus_dual */
		samsung,usi-serial-v2;
		clocks = <&clock GATE_PERIC1_TOP1_QCH_USI18_USI>, <&clock DOUT_DIV_CLK_PERIC1_USI18_USI>;
		clock-names = "gate_uart_clk20", "ipclk_uart20";
		samsung,usi-phandle = <&sysreg_peric1_2_usi>;
		samsung,usi-offset = <0x08>;
		status = "disabled";
	};

	/* USI_CMGP00_UART */
	serial_21: uart@14F00000 {
		compatible = "samsung,exynos-uart";
		samsung,separate-uart-clk;
		reg = <0x0 0x14F00000 0x100>;
		samsung,fifo-size = <64>;
		interrupts = <GIC_SPI INTREQ__USI_CMGP0 IRQ_TYPE_LEVEL_HIGH>;
		pinctrl-names = "default";
		pinctrl-0 = <&uart21_bus_single>; /* or _bus_dual */
		samsung,usi-serial-v2;
		clocks = <&clock GATE_USI_CMGP0_QCH>, <&clock DOUT_DIV_CLK_CMGP_USI0>;
		clock-names = "gate_uart_clk21", "ipclk_uart21";
		samsung,usi-phandle = <&sysreg_cmgp_usi>;
		samsung,usi-offset = <0x00>;
		status = "disabled";
	};

	/* USI_CMGP01_UART */
	serial_22: uart@14F20000 {
		compatible = "samsung,exynos-uart";
		samsung,separate-uart-clk;
		reg = <0x0 0x14F20000 0x100>;
		samsung,fifo-size = <64>;
		interrupts = <GIC_SPI INTREQ__USI_CMGP1 IRQ_TYPE_LEVEL_HIGH>;
		pinctrl-names = "default";
		pinctrl-0 = <&uart22_bus_single>; /* or _bus_dual */
		samsung,usi-serial-v2;
		clocks = <&clock GATE_USI_CMGP1_QCH>, <&clock DOUT_DIV_CLK_CMGP_USI1>;
		clock-names = "gate_uart_clk22", "ipclk_uart22";
		samsung,usi-phandle = <&sysreg_cmgp_usi>;
		samsung,usi-offset = <0x10>;
		status = "disabled";
	};

	/* USI_CMGP02_UART */
	serial_23: uart@14F40000 {
		compatible = "samsung,exynos-uart";
		samsung,separate-uart-clk;
		reg = <0x0 0x14F40000 0x100>;
		samsung,fifo-size = <64>;
		interrupts = <GIC_SPI INTREQ__USI_CMGP2 IRQ_TYPE_LEVEL_HIGH>;
		pinctrl-names = "default";
		pinctrl-0 = <&uart23_bus_single>; /* or _bus_dual */
		samsung,usi-serial-v2;
		clocks = <&clock GATE_USI_CMGP2_QCH>, <&clock DOUT_DIV_CLK_CMGP_USI2>;
		clock-names = "gate_uart_clk23", "ipclk_uart23";
		samsung,usi-phandle = <&sysreg_cmgp_usi>;
		samsung,usi-offset = <0x20>;
		status = "disabled";
	};

	/* USI_CMGP03_UART */
	serial_24: uart@14F60000 {
		compatible = "samsung,exynos-uart";
		samsung,separate-uart-clk;
		reg = <0x0 0x14F60000 0x100>;
		samsung,fifo-size = <64>;
		interrupts = <GIC_SPI INTREQ__USI_CMGP3 IRQ_TYPE_LEVEL_HIGH>;
		pinctrl-names = "default";
		pinctrl-0 = <&uart24_bus_single>; /* or _bus_dual */
		samsung,usi-serial-v2;
		clocks = <&clock GATE_USI_CMGP3_QCH>, <&clock DOUT_DIV_CLK_CMGP_USI3>;
		clock-names = "gate_uart_clk24", "ipclk_uart24";
		samsung,usi-phandle = <&sysreg_cmgp_usi>;
		samsung,usi-offset = <0x30>;
		status = "disabled";
	};
};
